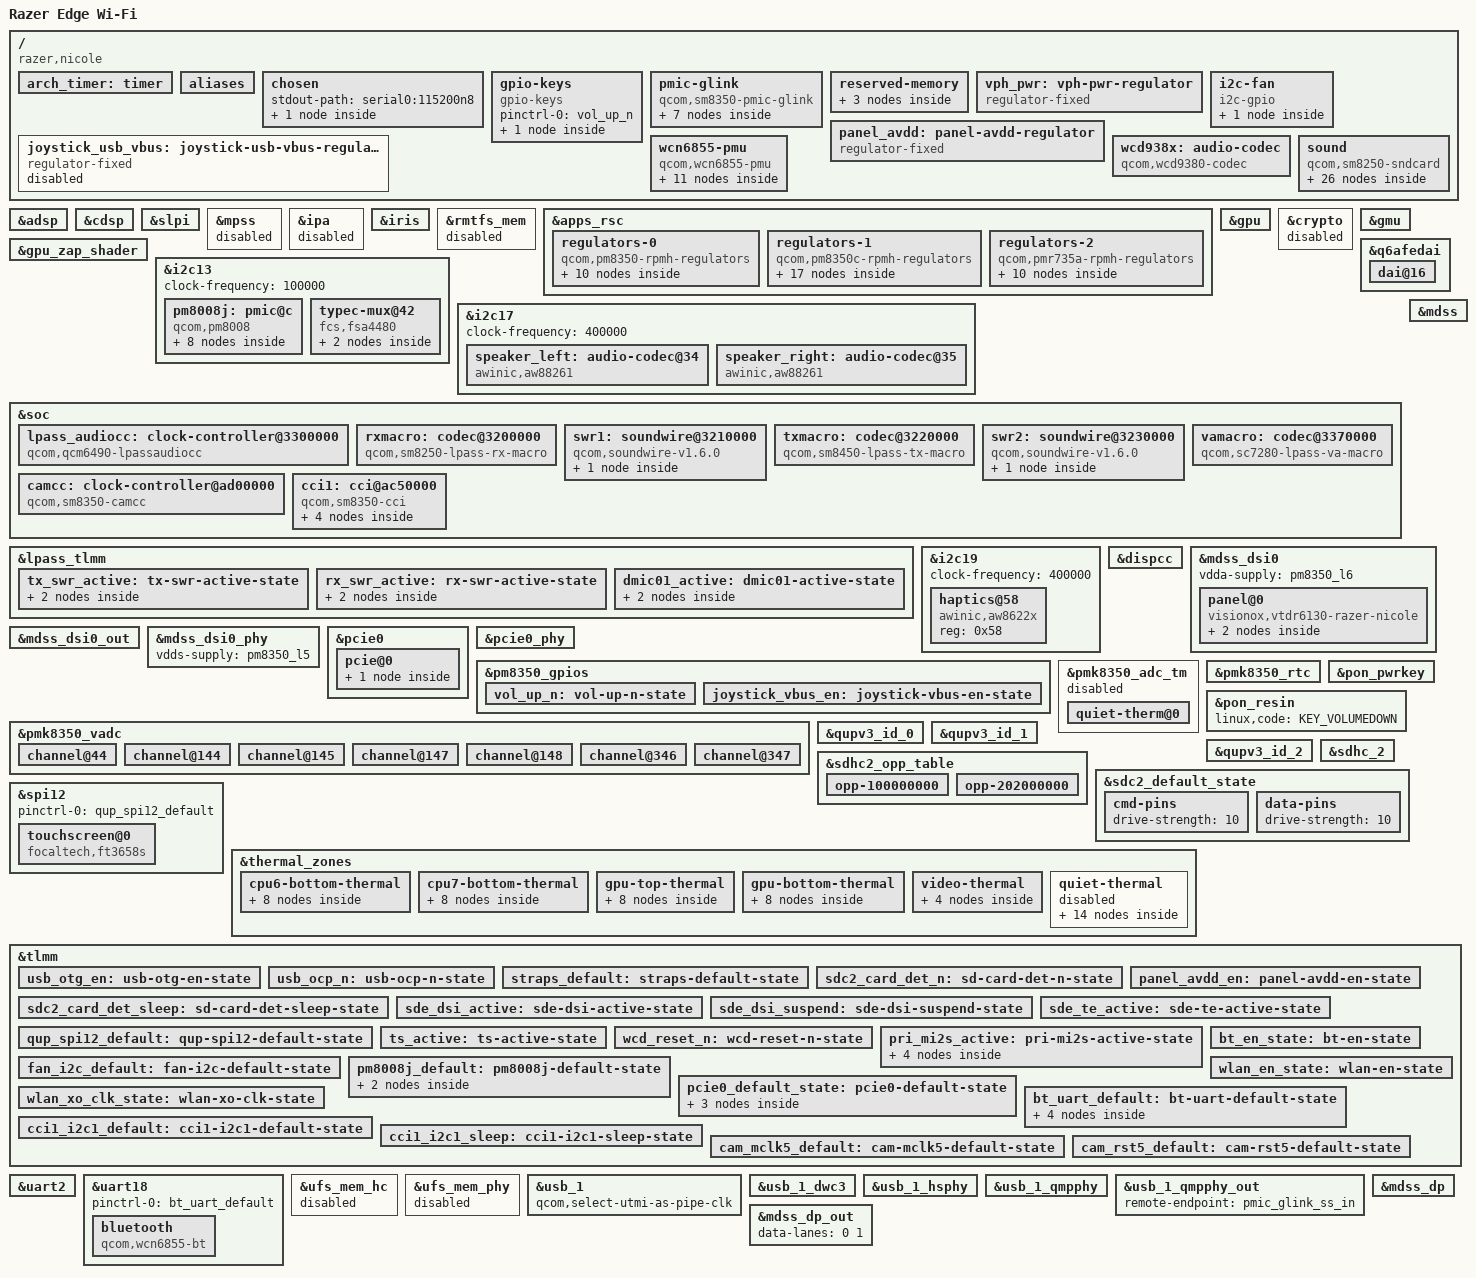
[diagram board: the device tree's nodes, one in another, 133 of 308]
// SPDX-License-Identifier: GPL-2.0-only
/*
 * Razer Edge Wi-Fi (RZ80-0461, codename "nicole")
 * Qualcomm SM8350 ("lahainap", marketed as Snapdragon G3x Gen 1), 6 GB RAM
 *
 * DRAFT mainline device tree - written before the device was connected.
 * Base structure follows sm8350-hdk.dts and sm8350-sony-xperia-sagami.dtsi.
 *
 * Source references (all paths relative to the Razer/LineageOS 5.4 kernel,
 * arch/arm64/boot/dts/vendor/qcom/ unless stated otherwise):
 *   nicole.dtsi   = lahainap-nicole.dtsi        (board file)
 *   qrd-common    = lahaina-qrd-common.dtsi     (included by nicole.dtsi:2)
 *   pmic-overlay  = lahaina-pmic-overlay.dtsi   (included by qrd-common:7)
 *   regulators    = lahaina-regulators.dtsi
 *   lahaina.dtsi  = SoC file (via lahainap.dtsi / lahainap-v2(.1).dtsi)
 *   pinctrl       = lahaina-pinctrl.dtsi
 * Effective downstream DT = lahainap*.dtb (base) + lahainap-nicole-overlay.dtbo
 * (Makefile:1-6, nicole.config CONFIG_BUILD_ARM64_DT_OVERLAY=y).
 *
 * PHASE RULES
 *   Phase 2 (first boot): microSD rootfs, USB gadget networking, simple-
 *   framebuffer console, buttons, remoteprocs. Internal UFS is DISABLED.
 *   Phase 3 nodes are present but status = "disabled" and marked PHASE 3.
 *
 * Anything marked TODO(cihaz) must be confirmed on the real device
 * (Phase 0 /sys/firmware/fdt dump, i2cdetect, gpioinfo, ...).
 */

/dts-v1/;

#include <dt-bindings/clock/qcom,lpassaudiocc-sc7280.h>
#include <dt-bindings/clock/qcom,sm8350-camcc.h>
#include <dt-bindings/gpio/gpio.h>
#include <dt-bindings/iio/qcom,spmi-adc7-pm8350.h>
#include <dt-bindings/iio/qcom,spmi-adc7-pm8350b.h>
#include <dt-bindings/iio/qcom,spmi-adc7-pmk8350.h>
#include <dt-bindings/input/input.h>
#include <dt-bindings/regulator/qcom,rpmh-regulator.h>
#include "sm8350.dtsi"
#include "pm8350.dtsi"
#include "pm8350b.dtsi"
#include "pm8350c.dtsi"
#include "pmk8350.dtsi"
#include "pmr735a.dtsi"
#include "pmr735b.dtsi"

/ {
	model = "Razer Edge Wi-Fi";
	compatible = "razer,nicole", "qcom,sm8350";
	chassis-type = "handset";

	/*
	 * ABL applies the Gunyah hypervisor's DTBOs on top of the DTB, and they
	 * reference the label "arch_timer" (Qualcomm's lahaina DT has it on the
	 * armv8 timer). Without it the overlay step fails and ABL drops to
	 * fastboot without a word (found 2026-10-25 by bisecting the __symbols__
	 * of LineageOS' SoC DTB, lab log). Build with -@.
	 */
	arch_timer: timer {
	};

	/*
	 * Downstream IDs: qcom,msm-id = <439 0x20001> (lahainap-v2.1.dtsi:6,
	 * 439 = QCOM_ID_SM8350 in mainline qcom,ids.h) and
	 * qcom,board-id = <0x1001f 0x02> (lahainap-nicole-overlay.dts:9).
	 * Sagami notes that adding msm/board-id on SM8350 can upset ABL, so they
	 * are left out on purpose. TODO(cihaz): if ABL refuses the DTB in
	 * "fastboot boot", try uncommenting these two lines:
	 *
	 * qcom,msm-id = <439 0x20001>;
	 * qcom,board-id = <0x1001f 0x02>;
	 */

	aliases {
		/* QUP SE3 debug UART @98c000, GPIO18/19 (lahaina-qupv3.dtsi:72-85,
		 * lahaina.dtsi:46 serial0). TODO(cihaz): test pads unknown. */
		serial0 = &uart2;
		mmc1 = &sdhc_2;
	};

	chosen {
		#address-cells = <2>;
		#size-cells = <2>;
		ranges;

		/*
		 * Kernel messages go to the debug UART (if pads are reachable);
		 * add "console=tty0" to the cmdline so the framebuffer console
		 * gets them too (see docs/dts-notlari.md).
		 */
		stdout-path = "serial0:115200n8";

		/*
		 * Bootloader continuous-splash framebuffer.
		 * Region: splash_memory "cont_splash_region" reg <0xe1000000 0x2300000>
		 * (lahaina.dtsi:516-519); disp_rdump_region uses the same base
		 * (display/lahaina-sde.dtsi:5-8). Panel is 1080x2400
		 * (display/dsi-panel-vtdr6130-dsc-fhd-plus-144hz-cmd.dtsi:54-55).
		 * 1080*2400*4 = 0x9e3400 bytes fits in the region.
		 * TODO(cihaz): verify format (a8r8g8b8 vs x8r8g8b8/r8g8b8) and
		 * stride (no padding assumed) by checking the picture on screen.
		 * The panel is mounted rotated (downstream qcom,mdss-dsi-panel-
		 * orientation = "180", panel dtsi:40; Android boots landscape,
		 * vendor.prop:101 ORIENTATION_90) -> use fbcon=rotate:N.
		 */
		framebuffer0: framebuffer@e1000000 {
			compatible = "simple-framebuffer";
			reg = <0x0 0xe1000000 0x0 0x2300000>;
			width = <1080>;
			height = <2400>;
			stride = <(1080 * 4)>;
			format = "a8r8g8b8";

			/*
			 * Keep the display path alive until a real DRM driver
			 * takes over: AXI clocks, MDSS GDSC (keeps MMCX up through
			 * the genpd hierarchy) and every rail the panel + DSI need,
			 * otherwise regulator/genpd/rpmhpd cleanup ~30 s after boot
			 * blanks the screen.
			 */
			clocks = <&gcc GCC_DISP_HF_AXI_CLK>,
				 <&gcc GCC_DISP_SF_AXI_CLK>;
			/*
			 * MMCX directly, not <&dispcc MDSS_GDSC>: dispcc stays disabled
			 * (see &dispcc below), the bootloader leaves MDSS_GDSC on.
			 * The HF TBUs carry the MDSS scanout through the SMMU; without
			 * pd_ignore_unused nothing else keeps them on.
			 */
			power-domains = <&rpmhpd RPMHPD_MMCX>,
					<&gcc HLOS1_VOTE_MMNOC_MMU_TBU_HF0_GDSC>,
					<&gcc HLOS1_VOTE_MMNOC_MMU_TBU_HF1_GDSC>;
			/*
			 * MDP scanout paths (sm8350.dtsi &mdss "mdp0-mem"/"mdp1-mem").
			 * Without a vote here the NoC stalls once the interconnect
			 * providers reach sync_state() (lab log, 25 Ekim);
			 * needs drivers/simpledrm/0001-...interconnect-bandwidth.patch.
			 */
			interconnects = <&mmss_noc MASTER_MDP0 0 &mc_virt SLAVE_EBI1 0>,
					<&mmss_noc MASTER_MDP1 0 &mc_virt SLAVE_EBI1 0>;
			vddio-supply = <&pm8350c_l12>;	/* panel vddio, display/lahaina-sde-display.dtsi:98 */
			vci-supply = <&pm8350c_l13>;	/* panel vdd 3.0 V, display/lahaina-sde-display.dtsi:99 */
			avdd-supply = <&panel_avdd>;	/* GPIO13 switch, nicole.dtsi:295-299 */
			dsi-vdda-supply = <&pm8350_l6>;	/* DSI 1.2 V, display/lahaina-sde.dtsi:90 */
			dsi-phy-supply = <&pm8350_l5>;	/* DSI PHY: lahaina-sde.dtsi:267 overrides :91 to L5B (0.88 V; downstream supply entry asks 0.912 V - TODO(cihaz): check regulators.txt) */
		};
	};

	gpio-keys {
		compatible = "gpio-keys";

		pinctrl-0 = <&vol_up_n>;
		pinctrl-names = "default";

		/* qrd-common:306-323 vol_up = pm8350_gpios 6, active low */
		key-vol-up {
			label = "Volume Up";
			linux,code = <KEY_VOLUMEUP>;
			gpios = <&pm8350_gpios 6 GPIO_ACTIVE_LOW>;
			debounce-interval = <15>;
			linux,can-disable;
			wakeup-source;
		};
	};

	/*
	 * Battery / charger through the ADSP (battery_charger, ucsi, altmode under
	 * qcom,pmic_glink, lahaina.dtsi:5558-5581). Enabled 2026-10-25 with the
	 * device's own adsp.mbn (Faz 3 extraction): qcom-battmgr reports status,
	 * capacity, voltage, current, temp; the ADSP charges by itself.
	 * Needs "qcom,sm8350" in the LIVE root compatible for the in-kernel PD mapper
	 * (the dtbo overlay used to replace it, see make-bootimg.sh d5 dtbo).
	 *
	 * D2 deneme C (31 Ekim): the Type-C graph as sm8350-hdk.dts:41-82: SS to
	 * usb_1_qmpphy (no redriver: NB7VPQ904M is QRD-only), SBU to the FSA4480,
	 * orientation from GPIO81 usb3phy_portselect (pinctrl:3652-3678), mdss_dp
	 * on two lanes. Razer's own DP node uses the same FSA4480 as AUX switch and
	 * the ADSP altmode for HPD (display/lahaina-sde.dtsi sde_dp).
	 */
	pmic-glink {
		compatible = "qcom,sm8350-pmic-glink", "qcom,pmic-glink";
		#address-cells = <1>;
		#size-cells = <0>;
		/* GPIO81 usb3phy_portselect (pinctrl:3652-3678), as sm8350-hdk */
		orientation-gpios = <&tlmm 81 GPIO_ACTIVE_HIGH>;

		/*
		 * Razer's OTG load switch (31 Ekim 2026): their 5.4 kernel drives
		 * global GPIO 356 high on battmgr notification 0x91 / a UFP partner
		 * and low on 0x90 (qti_battery_charger.c, ucsi.c). That is TLMM 48
		 * (TLMM base 308), the "ocp,control-gpio" of their qcom_ocp node;
		 * GPIO79 is the switch's active-low over-current flag, pulled up
		 * (nicole.dtsi:347-358, 501-508, drivers/soc/qcom/ocp_irq.c).
		 * Verified: a hub enumerates the moment 48 goes high and drops when
		 * it goes low. Keep GPIO78 ("usb_charge_contrl") low: with it high
		 * the hub never powered up. Consumer: drivers/typec ucsi_glink patch.
		 */
		otg-gpios = <&tlmm 48 GPIO_ACTIVE_HIGH>;
		ocp-gpios = <&tlmm 79 GPIO_ACTIVE_LOW>;
		pinctrl-0 = <&usb_otg_en>, <&usb_ocp_n>;
		pinctrl-names = "default";

		/*
		 * With the Type-C graph (altmode on) the ADSP's charger detection
		 * leaves the HS PHY non-driving, datapath overridden (CFG0 bit0,
		 * UTMI_CTRL0 OPMODE=01), ~11 ms after every sink attach: the Mac
		 * sees a dead device. ucsi_glink hands the datapath back through
		 * this PHY (31 Ekim 2026, measured with a 10 ms register watch).
		 */
		phys = <&usb_1_hsphy>;
		phy-names = "usb2";

		connector@0 {
			compatible = "usb-c-connector";
			reg = <0>;
			power-role = "dual";
			data-role = "dual";

			ports {
				#address-cells = <1>;
				#size-cells = <0>;

				/*
				 * No HS endpoint: wired to dwc3 it hands UCSI the role
				 * switch and device mode stalls (D1 deneme 1, D2 deneme
				 * C/E, 31 Ekim). nicole-usb-rol copies the role instead.
				 */
				port@0 {
					reg = <0>;
				};

				port@1 {
					reg = <1>;

					pmic_glink_ss_in: endpoint {
						remote-endpoint = <&usb_1_qmpphy_out>;
					};
				};

				port@2 {
					reg = <2>;

					pmic_glink_sbu: endpoint {
						remote-endpoint = <&fsa4480_sbu_mux>;
					};
				};
			};
		};
	};

	reserved-memory {
		/*
		 * All fixed carveouts of Razer's lahaina.dtsi:293-417 match
		 * mainline sm8350.dtsi:425-555 byte for byte (hyp, xbl_aop,
		 * cmd_db, smem, cpucp, cdsp_secure_heap, camera, video, cvp,
		 * adsp 0x86100000+0x2100000, slpi 0x88200000+0x1500000,
		 * cdsp 0x89700000+0x1e00000, ipa fw/gsi, gpu 0x8b51a000+0x2000,
		 * spss, modem 0x8b800000+0x10000000, hyp_reserved, trustedvm,
		 * qrtr/neuron shbufs, removed_mem). Only display regions are added
		 * here; rmtfs is handled below (&rmtfs_mem).
		 */

		/* lahaina.dtsi:516-519 (downstream has no no-map; we must not
		 * let Linux allocate the live scanout buffer) */
		cont_splash_mem: memory@e1000000 {
			reg = <0x0 0xe1000000 0x0 0x2300000>;
			no-map;
		};

		/* lahaina.dtsi:535-538 dfps_data_region, written by ABL */
		dfps_data_mem: memory@e3300000 {
			reg = <0x0 0xe3300000 0x0 0x100000>;
			no-map;
		};

		/*
		 * Crash log across a warm reset (pstore). Razer's DT has no such
		 * region; 0xffc00000 is what the other sm8350 phone in mainline
		 * uses (sm8350-sony-xperia-sagami.dtsi). On nicole it is plain
		 * System RAM (in Linux's CMA area, which simply moves). Added for
		 * the first suspend test (30 Ekim): the phone reset with no log.
		 */
		ramoops@ffc00000 {
			compatible = "ramoops";
			reg = <0x0 0xffc00000 0x0 0x100000>;
			record-size = <0x10000>;
			console-size = <0x40000>;
			pmsg-size = <0x20000>;
			ecc-size = <16>;
			no-map;
		};
	};

	vph_pwr: vph-pwr-regulator {
		compatible = "regulator-fixed";
		regulator-name = "vph_pwr";
		regulator-min-microvolt = <3700000>;
		regulator-max-microvolt = <3700000>;

		regulator-always-on;
		regulator-boot-on;
	};

	/*
	 * Panel AVDD load switch. Downstream: "display_panel_avdd" 5.5 V
	 * (display/lahaina-sde-display.dtsi:21-34) re-pointed by nicole to
	 * GPIO13, active LOW (nicole.dtsi:295-299, 320-330).
	 * regulator-boot-on: keep it on, the splash screen is using it.
	 */
	panel_avdd: panel-avdd-regulator {
		compatible = "regulator-fixed";
		regulator-name = "panel_avdd";
		regulator-min-microvolt = <5500000>;
		regulator-max-microvolt = <5500000>;
		regulator-enable-ramp-delay = <233>;
		gpio = <&tlmm 13 GPIO_ACTIVE_LOW>;
		regulator-boot-on;

		pinctrl-0 = <&panel_avdd_en>;
		pinctrl-names = "default";
	};

	/*
	 * PHASE 3: 5 V boost for the detachable controller ("joystick"),
	 * pm8350_gpios 8, always-on downstream (nicole.dtsi:542-553).
	 * TODO(cihaz): find out how the controller is wired (USB? usb1 is
	 * disabled on nicole, nicole.dtsi:577-587).
	 */
	joystick_usb_vbus: joystick-usb-vbus-regulator {
		compatible = "regulator-fixed";
		regulator-name = "joystick_usb_vbus";
		regulator-min-microvolt = <5000000>;
		regulator-max-microvolt = <5000000>;
		regulator-enable-ramp-delay = <600>;
		gpio = <&pm8350_gpios 8 GPIO_ACTIVE_HIGH>;
		enable-active-high;

		pinctrl-0 = <&joystick_vbus_en>;
		pinctrl-names = "default";

		status = "disabled";
	};

	/*
	 * PHASE 3: bit-banged I2C bus for the fan controller.
	 * nicole.dtsi:512-524: SDA GPIO8, SCL GPIO9, open drain, 5 us delay,
	 * pins pull-up / 16 mA (nicole.dtsi:449-460).
	 */
	i2c-fan {
		compatible = "i2c-gpio";
		sda-gpios = <&tlmm 8 (GPIO_ACTIVE_HIGH | GPIO_OPEN_DRAIN)>;
		scl-gpios = <&tlmm 9 (GPIO_ACTIVE_HIGH | GPIO_OPEN_DRAIN)>;
		i2c-gpio,delay-us = <5>;
		#address-cells = <1>;
		#size-cells = <0>;

		pinctrl-0 = <&fan_i2c_default>;
		pinctrl-names = "default";

		status = "okay";

		/*
		 * MAX31760 @0x50 (nicole.dtsi:526-539). Mainline driver
		 * drivers/hwmon/max31760.c ("adi,max31760") has NO regulator,
		 * GPIO or cooling-device support and the binding
		 * (hwmon/adi,max31760.yaml) has additionalProperties: false.
		 * The supply / GPIO / #cooling-cells properties below are a
		 * PROPOSED binding extension (driver work needed):
		 *   vdd  = pm8008j_l7, driver forces 3.3 V (max31760_fan.c:28-29)
		 *   fan  = pm8008j_l6, 2.8-2.9 V "VDD_FAN" (max31760_fan.c:30-31)
		 *   vcca = pm8350_s10, 1.8 V (max31760_fan.c:37-38)
		 *   GPIO78 "usb_charge_contrl", driven 0 at probe (max31760_fan.c:370-383)
		 *   GPIO93 "dpr_contrl", driven 1 at probe (max31760_fan.c:385-397)
		 * Fan levels 0..7 -> duty {0x00,0x4e,0x71,0x97,0xb2,0xcc,0xe8,0xff}
		 * (max31760_fan.c:80). docs/guvenlik-kurallari.md forbids turning the fan off.
		 */
		fancontroller: fan-controller@50 {
			compatible = "adi,max31760";
			reg = <0x50>;
			#cooling-cells = <2>;

			vdd-supply = <&pm8008j_l7>;
			fan-supply = <&pm8008j_l6>;
			vcca-supply = <&pm8350_s10>;
			usb-charge-en-gpios = <&tlmm 78 GPIO_ACTIVE_HIGH>;
			dpr-en-gpios = <&tlmm 93 GPIO_ACTIVE_HIGH>;
		};
	};

	/*
	 * PHASE 3: QCA6490 Wi-Fi/BT power sequencer (WCN6855 family,
	 * modelled on sm8450-hdk.dts). GPIOs: WLAN_EN 64, BT_EN 65,
	 * SW_CTRL 153 (lahaina.dtsi:5380-5382, 5646-5648), XO clock GPIO201
	 * (nicole.dtsi:5-12). Supplies from lahaina.dtsi:5395-5406 and
	 * 5649-5659: aon S2E, dig S11B, io S10B, rfa1 S1C, rfa2 S12B,
	 * antenna switch L7E. TODO(cihaz): the exact pmu-input mapping is
	 * inferred (downstream names differ from the mainline PMU inputs).
	 */
	wcn6855-pmu {
		compatible = "qcom,wcn6855-pmu";

		pinctrl-0 = <&bt_en_state>, <&wlan_en_state>, <&wlan_xo_clk_state>;
		pinctrl-names = "default";

		wlan-enable-gpios = <&tlmm 64 GPIO_ACTIVE_HIGH>;
		bt-enable-gpios = <&tlmm 65 GPIO_ACTIVE_HIGH>;
		swctrl-gpios = <&tlmm 153 GPIO_ACTIVE_HIGH>;
		xo-clk-gpios = <&tlmm 201 GPIO_ACTIVE_HIGH>;

		vddio-supply = <&pm8350_s10>;
		vddaon-supply = <&pmr735a_s2>;
		vddpmu-supply = <&pm8350_s12>;
		vddpmumx-supply = <&pmr735a_s2>;
		vddpmucx-supply = <&pm8350_s11>;
		vddrfa0p95-supply = <&pm8350_s11>;
		vddrfa1p3-supply = <&pm8350_s12>;
		vddrfa1p9-supply = <&pm8350c_s1>;
		vddpcie1p3-supply = <&pm8350_s12>;
		vddpcie1p9-supply = <&pm8350c_s1>;


		regulators {
			vreg_pmu_rfa_cmn_0p8: ldo0 {
				regulator-name = "vreg_pmu_rfa_cmn_0p8";
			};

			vreg_pmu_aon_0p8: ldo1 {
				regulator-name = "vreg_pmu_aon_0p8";
			};

			vreg_pmu_wlcx_0p8: ldo2 {
				regulator-name = "vreg_pmu_wlcx_0p8";
			};

			vreg_pmu_wlmx_0p8: ldo3 {
				regulator-name = "vreg_pmu_wlmx_0p8";
			};

			vreg_pmu_btcmx_0p8: ldo4 {
				regulator-name = "vreg_pmu_btcmx_0p8";
			};

			vreg_pmu_pcie_1p8: ldo5 {
				regulator-name = "vreg_pmu_pcie_1p8";
			};

			vreg_pmu_pcie_0p9: ldo6 {
				regulator-name = "vreg_pmu_pcie_0p9";
			};

			vreg_pmu_rfa_0p8: ldo7 {
				regulator-name = "vreg_pmu_rfa_0p8";
			};

			vreg_pmu_rfa_1p2: ldo8 {
				regulator-name = "vreg_pmu_rfa_1p2";
			};

			vreg_pmu_rfa_1p7: ldo9 {
				regulator-name = "vreg_pmu_rfa_1p7";
			};
		};
	};
};

/*
 * Remoteprocs. Carveouts identical to mainline (see reserved-memory).
 * Downstream PAS ids: adsp 1 (lahaina.dtsi:4492), cdsp 18 (:4539),
 * slpi 12 (:5125) - same as mainline sm8350-adsp/cdsp/slpi-pas.
 * Firmware comes from the device's modem/NON-HLOS partition as split
 * .mdt/.bNN files; squash to .mbn (pil-squasher) into
 * /lib/firmware/qcom/sm8350/razer/nicole/. If the files are absent the
 * remoteproc simply stays offline.
 */
&adsp {
	firmware-name = "qcom/sm8350/razer/nicole/adsp.mbn";
	status = "okay";
};

&cdsp {
	firmware-name = "qcom/sm8350/razer/nicole/cdsp.mbn";
	status = "okay";
};

&slpi {
	firmware-name = "qcom/sm8350/razer/nicole/slpi.mbn";
	status = "okay";
};

/*
 * Wi-Fi SKU: no modem. The 5G SKU uses an external Quectel module
 * (nicole.dtsi:494-499, lineage-device init.target.rc Quectel RIL), so
 * MPSS stays disabled (sm8350.dtsi default) and IPA too (lahainap.dtsi:9-11
 * disables ipa_hw).
 */
&mpss {
	status = "disabled";
};

&ipa {
	status = "disabled";
};

/*
 * D4 (31 Ekim 2026): hardware video decode/encode (iris, VPU 2.0). The firmware is the
 * device's own, signed for this SoC: vendor/firmware/vpu20_4v.mbn (lahaina-vidc.dtsi:37),
 * put on the phone by scripts/lab/video-firmware.sh, never packaged. linux-firmware has
 * no sm8350 VPU file (sm8350-hdk's vpu20_p4_sm8350.mbn is not in it). pil_video_mem
 * (0x85700000+0x500000, sm8350.dtsi) is Razer's carveout too (lahaina.dtsi:339-342).
 */
&iris {
	firmware-name = "qcom/sm8350/razer/nicole/vpu20_4v.mbn";

	status = "okay";
};

/*
 * Mainline reserves rmtfs at a fixed 0x9b800000+0x280000; Razer allocates
 * rmtfs dynamically (qcom,rmtfs_sharedmem reg <0 0x280000>,
 * lahaina.dtsi:3026-3031), so Android uses that range as normal RAM.
 * Only the modem needs rmtfs -> drop the carveout.
 */
&rmtfs_mem {
	status = "disabled";
};

&apps_rsc {
	/*
	 * PM8350 (PMIC "b"). Voltages = lahaina-regulators.dtsi ranges
	 * (never wider). Labels follow the downstream names so that
	 * S10B == pm8350_s10, L5B == pm8350_l5 etc.
	 * ARC (level) rails S5/S6/S9/L4/L8 are not listed.
	 */
	regulators-0 {
		compatible = "qcom,pm8350-rpmh-regulators";
		qcom,pmic-id = "b";

		vdd-s1-supply = <&vph_pwr>;
		vdd-s2-supply = <&vph_pwr>;
		vdd-s3-supply = <&vph_pwr>;
		vdd-s4-supply = <&vph_pwr>;
		vdd-s5-supply = <&vph_pwr>;
		vdd-s6-supply = <&vph_pwr>;
		vdd-s7-supply = <&vph_pwr>;
		vdd-s8-supply = <&vph_pwr>;
		vdd-s9-supply = <&vph_pwr>;
		vdd-s10-supply = <&vph_pwr>;
		vdd-s11-supply = <&vph_pwr>;
		vdd-s12-supply = <&vph_pwr>;

		vdd-l1-l4-supply = <&pm8350_s11>;
		vdd-l2-l7-supply = <&vreg_bob>;
		vdd-l3-l5-supply = <&vreg_bob>;
		vdd-l6-l9-l10-supply = <&pm8350_s11>;

		/* regulators:121-126 */
		pm8350_s10: smps10 {
			regulator-name = "pm8350_s10";
			regulator-min-microvolt = <1800000>;
			regulator-max-microvolt = <1800000>;
			regulator-initial-mode = <RPMH_REGULATOR_MODE_HPM>;
		};

		/* regulators:133-138 */
		pm8350_s11: smps11 {
			regulator-name = "pm8350_s11";
			regulator-min-microvolt = <752000>;
			regulator-max-microvolt = <1012000>;
			regulator-initial-mode = <RPMH_REGULATOR_MODE_HPM>;
		};

		/* regulators:150-156 */
		pm8350_s12: smps12 {
			regulator-name = "pm8350_s12";
			regulator-min-microvolt = <1224000>;
			regulator-max-microvolt = <1360000>;
			regulator-initial-mode = <RPMH_REGULATOR_MODE_HPM>;
		};

		/* regulators:168-174, DSI PHY 0.9 V + USB QMP PHY */
		pm8350_l1: ldo1 {
			regulator-name = "pm8350_l1";
			regulator-min-microvolt = <912000>;
			regulator-max-microvolt = <920000>;
			regulator-initial-mode = <RPMH_REGULATOR_MODE_HPM>;
		};

		/* regulators:187-193, USB HS PHY 3.1 V */
		pm8350_l2: ldo2 {
			regulator-name = "pm8350_l2";
			regulator-min-microvolt = <3072000>;
			regulator-max-microvolt = <3072000>;
			regulator-initial-mode = <RPMH_REGULATOR_MODE_HPM>;
		};

		/* regulators:207-213 */
		pm8350_l3: ldo3 {
			regulator-name = "pm8350_l3";
			regulator-min-microvolt = <904000>;
			regulator-max-microvolt = <904000>;
			regulator-initial-mode = <RPMH_REGULATOR_MODE_HPM>;
		};

		/* regulators:242-248, USB HS PHY / UFS PHY / PCIe 0.88 V */
		pm8350_l5: ldo5 {
			regulator-name = "pm8350_l5";
			regulator-min-microvolt = <880000>;
			regulator-max-microvolt = <888000>;
			regulator-initial-mode = <RPMH_REGULATOR_MODE_HPM>;
			/*
			 * Fixed HPM (no allow-set-load / LPM), a precaution: shared PHY rail
			 * (USB HS PHY PLL, UFS PHY, DSI PHY) and the USB PHY votes no load,
			 * so a UFS PHY load drop could otherwise put it in LPM. (The NCM
			 * link failures of 2026-10-25 that prompted this were the Mac's
			 * screen lock holding back new USB accessories, not this rail.)
			 */
			regulator-allowed-modes = <RPMH_REGULATOR_MODE_HPM>;
		};

		/* regulators:282-288, DSI 1.2 V / PHY PLLs */
		pm8350_l6: ldo6 {
			regulator-name = "pm8350_l6";
			regulator-min-microvolt = <1200000>;
			regulator-max-microvolt = <1208000>;
			regulator-initial-mode = <RPMH_REGULATOR_MODE_HPM>;
			/*
			 * Fixed HPM (no allow-set-load / LPM), a precaution: shared PHY rail
			 * (USB HS PHY PLL, UFS PHY, DSI PHY) and the USB PHY votes no load,
			 * so a UFS PHY load drop could otherwise put it in LPM. (The NCM
			 * link failures of 2026-10-25 that prompted this were the Mac's
			 * screen lock holding back new USB accessories, not this rail.)
			 */
			regulator-allowed-modes = <RPMH_REGULATOR_MODE_HPM>;
		};

		/* regulators:302-308, UFS VCC (UFS disabled in phase 2) */
		pm8350_l7: ldo7 {
			regulator-name = "pm8350_l7";
			regulator-min-microvolt = <2400000>;
			regulator-max-microvolt = <3008000>;
			regulator-initial-mode = <RPMH_REGULATOR_MODE_HPM>;
			regulator-allow-set-load;
			regulator-allowed-modes = <RPMH_REGULATOR_MODE_LPM
						   RPMH_REGULATOR_MODE_HPM>;
		};

		/* regulators:336-342, UFS VCCQ */
		pm8350_l9: ldo9 {
			regulator-name = "pm8350_l9";
			regulator-min-microvolt = <1200000>;
			regulator-max-microvolt = <1200000>;
			regulator-initial-mode = <RPMH_REGULATOR_MODE_HPM>;
			regulator-allow-set-load;
			regulator-allowed-modes = <RPMH_REGULATOR_MODE_LPM
						   RPMH_REGULATOR_MODE_HPM>;
		};
	};

	/* PM8350C (PMIC "c"). ARC rails S2/S4/S6/S8 not listed. */
	regulators-1 {
		compatible = "qcom,pm8350c-rpmh-regulators";
		qcom,pmic-id = "c";

		vdd-s1-supply = <&vph_pwr>;
		vdd-s2-supply = <&vph_pwr>;
		vdd-s3-supply = <&vph_pwr>;
		vdd-s4-supply = <&vph_pwr>;
		vdd-s5-supply = <&vph_pwr>;
		vdd-s6-supply = <&vph_pwr>;
		vdd-s7-supply = <&vph_pwr>;
		vdd-s8-supply = <&vph_pwr>;
		vdd-s9-supply = <&vph_pwr>;
		vdd-s10-supply = <&vph_pwr>;

		vdd-l1-l12-supply = <&pm8350c_s1>;
		vdd-l2-l8-supply = <&pm8350c_s1>;
		vdd-l3-l4-l5-l7-l13-supply = <&vreg_bob>;
		vdd-l6-l9-l11-supply = <&vreg_bob>;
		vdd-l10-supply = <&pm8350_s12>;

		vdd-bob-supply = <&vph_pwr>;

		/* regulators:349-354 */
		pm8350c_s1: smps1 {
			regulator-name = "pm8350c_s1";
			regulator-min-microvolt = <1800000>;
			regulator-max-microvolt = <1952000>;
			regulator-initial-mode = <RPMH_REGULATOR_MODE_HPM>;
		};

		/* regulators:377-382 */
		pm8350c_s3: smps3 {
			regulator-name = "pm8350c_s3";
			regulator-min-microvolt = <300000>;
			regulator-max-microvolt = <704000>;
			regulator-initial-mode = <RPMH_REGULATOR_MODE_HPM>;
		};

		/* regulators:504-509 */
		pm8350c_s10: smps10 {
			regulator-name = "pm8350c_s10";
			regulator-min-microvolt = <1048000>;
			regulator-max-microvolt = <1128000>;
			regulator-initial-mode = <RPMH_REGULATOR_MODE_HPM>;
		};

		/* regulators:522-528, USB HS PHY 1.8 V */
		pm8350c_l1: ldo1 {
			regulator-name = "pm8350c_l1";
			regulator-min-microvolt = <1800000>;
			regulator-max-microvolt = <1800000>;
			regulator-initial-mode = <RPMH_REGULATOR_MODE_HPM>;
		};

		/* regulators:561-567 */
		pm8350c_l2: ldo2 {
			regulator-name = "pm8350c_l2";
			regulator-min-microvolt = <1800000>;
			regulator-max-microvolt = <1800000>;
			regulator-initial-mode = <RPMH_REGULATOR_MODE_HPM>;
		};

		/* regulators:579-585 - touch vdd (nicole.dtsi:156). NOTE: Razer
		 * fixes L3C at 3.008 V (sagami uses 3.304 V - do not copy). */
		pm8350c_l3: ldo3 {
			regulator-name = "pm8350c_l3";
			regulator-min-microvolt = <3008000>;
			regulator-max-microvolt = <3008000>;
			regulator-initial-mode = <RPMH_REGULATOR_MODE_HPM>;
		};

		/* regulators:597-603 */
		pm8350c_l4: ldo4 {
			regulator-name = "pm8350c_l4";
			regulator-min-microvolt = <1704000>;
			regulator-max-microvolt = <3000000>;
			regulator-initial-mode = <RPMH_REGULATOR_MODE_HPM>;
		};

		/* regulators:615-621 */
		pm8350c_l5: ldo5 {
			regulator-name = "pm8350c_l5";
			regulator-min-microvolt = <1704000>;
			regulator-max-microvolt = <3000000>;
			regulator-initial-mode = <RPMH_REGULATOR_MODE_HPM>;
		};

		/* regulators:634-640 - SD card I/O (qrd-common:45-46 asks
		 * 1.808-2.96 V) */
		pm8350c_l6: ldo6 {
			regulator-name = "pm8350c_l6";
			regulator-min-microvolt = <1800000>;
			regulator-max-microvolt = <2960000>;
			regulator-initial-mode = <RPMH_REGULATOR_MODE_HPM>;
		};

		/* regulators:654-660 */
		pm8350c_l7: ldo7 {
			regulator-name = "pm8350c_l7";
			regulator-min-microvolt = <3008000>;
			regulator-max-microvolt = <3008000>;
			regulator-initial-mode = <RPMH_REGULATOR_MODE_HPM>;
		};

		/* regulators:672-678 - touch vcc_i2c / iovdd (nicole.dtsi:157) */
		pm8350c_l8: ldo8 {
			regulator-name = "pm8350c_l8";
			regulator-min-microvolt = <1800000>;
			regulator-max-microvolt = <1800000>;
			regulator-initial-mode = <RPMH_REGULATOR_MODE_HPM>;
		};

		/*
		 * regulators:691-697 allows 2.96-3.008 V; the SD consumer asks
		 * 2.95-2.96 V (qrd-common:41-42). Clamp max to 2.96 V like
		 * sagami (SDHCI expects 2.96 V) - still inside Razer's range.
		 */
		pm8350c_l9: ldo9 {
			regulator-name = "pm8350c_l9";
			regulator-min-microvolt = <2960000>;
			regulator-max-microvolt = <2960000>;
			regulator-initial-mode = <RPMH_REGULATOR_MODE_HPM>;
		};

		/* regulators:711-717 */
		pm8350c_l10: ldo10 {
			regulator-name = "pm8350c_l10";
			regulator-min-microvolt = <1200000>;
			regulator-max-microvolt = <1200000>;
			regulator-initial-mode = <RPMH_REGULATOR_MODE_HPM>;
		};

		/* regulators:729-735 */
		pm8350c_l11: ldo11 {
			regulator-name = "pm8350c_l11";
			regulator-min-microvolt = <2400000>;
			regulator-max-microvolt = <3008000>;
			regulator-initial-mode = <RPMH_REGULATOR_MODE_HPM>;
		};

		/* regulators:748-754 - panel vddio, nicole sets 1.86 V
		 * (nicole.dtsi:302-305) */
		pm8350c_l12: ldo12 {
			regulator-name = "pm8350c_l12";
			regulator-min-microvolt = <1800000>;
			regulator-max-microvolt = <2000000>;
			regulator-initial-mode = <RPMH_REGULATOR_MODE_HPM>;
		};

		/* regulators:769-775 - panel vdd/vci 3.0 V
		 * (display/lahaina-sde-display-common.dtsi:49-57) */
		pm8350c_l13: ldo13 {
			regulator-name = "pm8350c_l13";
			regulator-min-microvolt = <3000000>;
			regulator-max-microvolt = <3000000>;
			regulator-initial-mode = <RPMH_REGULATOR_MODE_HPM>;
		};

		/* regulators:784-789 */
		vreg_bob: bob {
			regulator-name = "pm8350c_bob";
			regulator-min-microvolt = <3008000>;
			regulator-max-microvolt = <3960000>;
			regulator-initial-mode = <RPMH_REGULATOR_MODE_AUTO>;
		};
	};

	/*
	 * PM8350B L1 ("ldod1", 1.2 V, regulators:801-807) is not described:
	 * same situation as sagami (no mainline rpmh entry used so far).
	 */

	/* PMR735A (PMIC "e"), regulators:814-969 */
	regulators-2 {
		compatible = "qcom,pmr735a-rpmh-regulators";
		qcom,pmic-id = "e";

		vdd-s1-supply = <&vph_pwr>;
		vdd-s2-supply = <&vph_pwr>;
		vdd-s3-supply = <&vph_pwr>;

		vdd-l1-l2-supply = <&pmr735a_s2>;
		vdd-l3-supply = <&pmr735a_s1>;
		vdd-l4-supply = <&pm8350c_s1>;
		vdd-l5-l6-supply = <&pm8350c_s1>;
		vdd-l7-bob-supply = <&vreg_bob>;

		pmr735a_s1: smps1 {
			regulator-name = "pmr735a_s1";
			regulator-min-microvolt = <1200000>;
			regulator-max-microvolt = <1280000>;
		};

		/* Wi-Fi "aon" rail (lahaina.dtsi:5395-5396 asks 1.012 V) */
		pmr735a_s2: smps2 {
			regulator-name = "pmr735a_s2";
			regulator-min-microvolt = <500000>;
			regulator-max-microvolt = <1020000>;
		};

		pmr735a_s3: smps3 {
			regulator-name = "pmr735a_s3";
			regulator-min-microvolt = <2200000>;
			regulator-max-microvolt = <2352000>;
		};

		pmr735a_l1: ldo1 {
			regulator-name = "pmr735a_l1";
			regulator-min-microvolt = <912000>;
			regulator-max-microvolt = <912000>;
		};

		pmr735a_l2: ldo2 {
			regulator-name = "pmr735a_l2";
			regulator-min-microvolt = <1200000>;
			regulator-max-microvolt = <1200000>;
		};

		pmr735a_l3: ldo3 {
			regulator-name = "pmr735a_l3";
			regulator-min-microvolt = <1200000>;
			regulator-max-microvolt = <1200000>;
		};

		pmr735a_l4: ldo4 {
			regulator-name = "pmr735a_l4";
			regulator-min-microvolt = <1776000>;
			regulator-max-microvolt = <1872000>;
		};

		pmr735a_l5: ldo5 {
			regulator-name = "pmr735a_l5";
			regulator-min-microvolt = <800000>;
			regulator-max-microvolt = <800000>;
		};

		pmr735a_l6: ldo6 {
			regulator-name = "pmr735a_l6";
			regulator-min-microvolt = <480000>;
			regulator-max-microvolt = <904000>;
		};

		/* Wi-Fi/BT antenna switch 2.8 V (lahaina.dtsi:5405-5406) */
		pmr735a_l7: ldo7 {
			regulator-name = "pmr735a_l7";
			regulator-min-microvolt = <2800000>;
			regulator-max-microvolt = <2800000>;
			regulator-initial-mode = <RPMH_REGULATOR_MODE_HPM>;
			/* No consumer binding for the antenna switch: keep it on */
			regulator-always-on;
		};
	};
};

/*
 * Adreno 660. Zap shader carveout pil_gpu_mem is identical. The zap shader
 * is Razer's (vendor_b /firmware/a660_zap.mdt, squashed; docs/guvenlik-kurallari.md §8, 29 Ekim):
 * local only, never packaged. SQE/GMU firmware: firmware-qcom-adreno-a660.
 */
&gpu {
	status = "okay";
};

/*
 * No QCE driver in the kernel config: an unbound crypto node holds both
 * interconnect providers' sync_state(), so the boot-time maximum bandwidth
 * (DDR/NoC clocks) is never dropped. Safe to release only because the
 * framebuffer node votes for the MDP scanout paths (see framebuffer0).
 */
&crypto {
	status = "disabled";
};

/*
 * On together with the GPU: an enabled GMU without a bound driver would hold
 * gcc and gpucc sync_state(), so unused GDSCs (UFS, video, SF TBUs) stay on.
 */
&gmu {
	status = "okay";
};

&gpu_zap_shader {
	firmware-name = "qcom/sm8350/razer/nicole/a660_zap.mbn";
};

/*
 * PHASE 3: QUP SE13 I2C (lahaina-qupv3.dtsi:737-756, pins GPIO0/1
 * pinctrl:1440-1450). NOTE: downstream marks this SE "qcom,shared"
 * (lahaina-qupv3.dtsi:754, shared with another execution environment);
 * mainline i2c-qcom-geni has no equivalent. Clock not specified
 * downstream -> 100 kHz like sagami.
 * Expected devices (TODO(cihaz): confirm with i2cdetect on bus 13):
 *   0x0c/0x0d PM8008 "j"  (pmic-overlay:168-273; "i" @0x08/0x09 is
 *                          disabled by nicole.dtsi:166-170, and its reset
 *                          GPIO33 is listed as NC in nicole.dtsi:333-345)
 *   0x42      FSA4480     (lahaina-audio.dtsi:204-209)
 *   0x1c      NB7VPQ904M  (ONLY in lahaina-qrd.dtsi:31-65, which nicole
 *                          does NOT include -> presence unverified)
 */
&i2c13 {
	clock-frequency = <100000>;
	/* M2: on for PM8008 "j" (fan supplies); the USB-C chips below stay
	 * off until the Type-C graph is verified */
	status = "okay";

	/*
	 * PM8008 "j": mainline "qcom,pm8008" uses reg = first address and
	 * reaches the regulator block at reg+1 (0x0d) itself.
	 * Supplies: pmic-overlay:203-208 (l1/l2 S12B, l3/l4 S1C, l5-l7 BOB).
	 * Reset: GPIO35, driven high when active (pinctrl:2880-2892).
	 * TODO(cihaz): interrupt is not described downstream. On the HDK the
	 * pin pairs are 32/33 (PM8008_1 IRQ/RESET) and 34/35 (PM8008_2
	 * IRQ/RESET) (sm8350-hdk.dts gpio-line-names) -> GPIO34 assumed.
	 * Consumers: fan (vdd l7, fan l6), front camera (l1/l3/l5,
	 * camera/lahaina-camera-sensor-nicole.dtsi:14-16).
	 */
	pm8008j: pmic@c {
		compatible = "qcom,pm8008";
		reg = <0xc>;

		interrupts-extended = <&tlmm 34 IRQ_TYPE_EDGE_RISING>;
		reset-gpios = <&tlmm 35 GPIO_ACTIVE_LOW>;

		vdd-l1-l2-supply = <&pm8350_s12>;
		vdd-l3-l4-supply = <&pm8350c_s1>;
		vdd-l5-supply = <&vreg_bob>;
		vdd-l6-supply = <&vreg_bob>;
		vdd-l7-supply = <&vreg_bob>;

		pinctrl-0 = <&pm8008j_default>;
		pinctrl-names = "default";

		gpio-controller;
		#gpio-cells = <2>;
		gpio-ranges = <&pm8008j 0 0 2>;

		interrupt-controller;
		#interrupt-cells = <2>;

		#thermal-sensor-cells = <0>;

		regulators {
			/* pmic-overlay:210-217, nicole.dtsi:179-182 forces 1.2 V */
			pm8008j_l1: ldo1 {
				regulator-name = "pm8008j_l1";
				regulator-min-microvolt = <1200000>;
				regulator-max-microvolt = <1200000>;
			};

			/* pmic-overlay:219-226 */
			pm8008j_l2: ldo2 {
				regulator-name = "pm8008j_l2";
				regulator-min-microvolt = <944000>;
				regulator-max-microvolt = <1056000>;
			};

			/* pmic-overlay:228-235 */
			/* front camera vio: 1.8 V fixed, as the downstream sensor
			 * node asks (camera/lahaina-camera-sensor-nicole.dtsi:61) */
			pm8008j_l3: ldo3 {
				regulator-name = "pm8008j_l3";
				regulator-min-microvolt = <1800000>;
				regulator-max-microvolt = <1800000>;
			};

			/* pmic-overlay:237-244 */
			pm8008j_l4: ldo4 {
				regulator-name = "pm8008j_l4";
				regulator-min-microvolt = <1728000>;
				regulator-max-microvolt = <1800000>;
			};

			/* pmic-overlay:246-253 */
			/* front camera vana: 2.8 V fixed (same downstream line) */
			pm8008j_l5: ldo5 {
				regulator-name = "pm8008j_l5";
				regulator-min-microvolt = <2800000>;
				regulator-max-microvolt = <2800000>;
			};

			/* pmic-overlay:255-262 + nicole.dtsi:184-186 (max 2.9 V):
			 * fan motor supply */
			pm8008j_l6: ldo6 {
				regulator-name = "pm8008j_l6";
				regulator-min-microvolt = <2800000>;
				regulator-max-microvolt = <2900000>;
				/* mainline max31760 takes no supplies; the fan
				 * must never be unpowered (docs/guvenlik-kurallari.md) */
				regulator-always-on;
			};

			/* nicole.dtsi:188-191 (3.2-3.3 V; overrides 2.808-3.6 V
			 * of pmic-overlay:264-271): fan controller VDD */
			pm8008j_l7: ldo7 {
				regulator-name = "pm8008j_l7";
				regulator-min-microvolt = <3200000>;
				regulator-max-microvolt = <3300000>;
				regulator-always-on;
			};
		};
	};

	/*
	 * FSA4480 USB-C SBU/analog-audio switch (lahaina-audio.dtsi:204-209).
	 * Downstream gives no IRQ and no supply. TODO(cihaz): IRQ GPIO;
	 * vcc assumed BOB like sm8350-hdk.dts:417-432.
	 */
	typec-mux@42 {
		compatible = "fcs,fsa4480";
		reg = <0x42>;

		vcc-supply = <&vreg_bob>;

		mode-switch;
		orientation-switch;

		status = "okay";

		port {
			fsa4480_sbu_mux: endpoint {
				remote-endpoint = <&pmic_glink_sbu>;
			};
		};
	};

};

/*
 * Speakers: two Awinic AW88261 smart amps on QUP SE17 I2C (GPIO72/73,
 * pinctrl:1552-1564), chip ID 0x2113 read on the device (28 Oct 2026).
 * nicole.dtsi:193-223: @0x34 = channel 0 (left, IRQ GPIO90), @0x35 =
 * channel 1 (right, IRQ GPIO119); no reset line. Fed over PRI MI2S RX on
 * SD0 (nicole.dtsi:59-65: qcom,msm-mi2s-lines = <1>); SD1 carries the amps'
 * I/V feedback (TX) for Razer's ADSP speaker protection, not used here.
 * Firmware: Razer's vendor/firmware/aw882xx_acf.bin (an AW88261 ACF with
 * profiles for both channels), installed under the name below.
 * dvdd: no supply in the downstream DT; the amps answer on I2C from boot,
 * so it is an always-on 1.8 V rail. S10B is the board's 1.8 V I/O rail
 * (WCD938x, fan, WLAN I/O) -- assumption, TODO: confirm from schematics.
 */
&i2c17 {
	clock-frequency = <400000>;
	status = "okay";

	speaker_left: audio-codec@34 {
		compatible = "awinic,aw88261";
		reg = <0x34>;
		#sound-dai-cells = <0>;
		dvdd-supply = <&pm8350_s10>;
		awinic,audio-channel = <0>;
		firmware-name = "qcom/sm8350/razer/nicole/aw88261_acf.bin";
		sound-name-prefix = "Left";
	};

	speaker_right: audio-codec@35 {
		compatible = "awinic,aw88261";
		reg = <0x35>;
		#sound-dai-cells = <0>;
		dvdd-supply = <&pm8350_s10>;
		awinic,audio-channel = <1>;
		firmware-name = "qcom/sm8350/razer/nicole/aw88261_acf.bin";
		sound-name-prefix = "Right";
	};
};

&q6afedai {
	dai@16 {
		reg = <PRIMARY_MI2S_RX>;
		qcom,sd-lines = <0>;
	};
};

/ {
	/*
	 * WCD938x (lahaina-audio-overlay.dtsi:230-282): reset GPIO88, rxtx/io/buck
	 * from S10B 1.8 V, mic bias from BOB, all four mic biases 1.8 V. Register
	 * access goes over the TX SoundWire bus (wcd_tx), playback over RX (wcd_rx).
	 * nicole has no 3.5 mm jack (USB-C analog audio via FSA4480); the MBHC
	 * thresholds are the SM8450 HDK ones until that path is brought up.
	 */
	wcd938x: audio-codec {
		compatible = "qcom,wcd9380-codec";
		pinctrl-0 = <&wcd_reset_n>;
		pinctrl-names = "default";
		reset-gpios = <&tlmm 88 GPIO_ACTIVE_LOW>;

		vdd-buck-supply = <&pm8350_s10>;
		vdd-rxtx-supply = <&pm8350_s10>;
		vdd-io-supply = <&pm8350_s10>;
		vdd-mic-bias-supply = <&vreg_bob>;

		qcom,micbias1-microvolt = <1800000>;
		qcom,micbias2-microvolt = <1800000>;
		qcom,micbias3-microvolt = <1800000>;
		qcom,micbias4-microvolt = <1800000>;
		qcom,mbhc-buttons-vthreshold-microvolt = <75000 150000 237000 500000 500000 500000 500000 500000>;
		qcom,mbhc-headset-vthreshold-microvolt = <1700000>;
		qcom,mbhc-headphone-vthreshold-microvolt = <50000>;
		qcom,rx-device = <&wcd_rx>;
		qcom,tx-device = <&wcd_tx>;

		#sound-dai-cells = <1>;
	};

	sound {
		compatible = "qcom,sm8250-sndcard";
		model = "Razer-Edge";
		pinctrl-0 = <&pri_mi2s_active>;
		pinctrl-names = "default";
		/*
		 * nicole.dtsi:79-110: the digital mics are powered from WCD938x
		 * MIC BIAS1 / MIC BIAS3 (which DMIC sits on which bias is not
		 * certain, so both mics pull both), the analog mic from MIC BIAS2.
		 */
		audio-routing = "VA DMIC0", "MIC BIAS1",
				"VA DMIC0", "MIC BIAS3",
				"VA DMIC1", "MIC BIAS1",
				"VA DMIC1", "MIC BIAS3",
				"AMIC2", "MIC BIAS2",
				/* USB-C analog headset (FSA4480): RX macro -> WCD938x HPH */
				"IN1_HPHL", "HPHL_OUT",
				"IN2_HPHR", "HPHR_OUT";

		mm1-dai-link {
			link-name = "MultiMedia1";

			cpu {
				sound-dai = <&q6asmdai MSM_FRONTEND_DAI_MULTIMEDIA1>;
			};
		};

		mm2-dai-link {
			link-name = "MultiMedia2";

			cpu {
				sound-dai = <&q6asmdai MSM_FRONTEND_DAI_MULTIMEDIA2>;
			};
		};

		/* DisplayPort audio front end (hw:0,2), kept after MM1/MM2 so they keep 0 and 1 */
		mm3-dai-link {
			link-name = "MultiMedia3";

			cpu {
				sound-dai = <&q6asmdai MSM_FRONTEND_DAI_MULTIMEDIA3>;
			};
		};

		va-dai-link {
			link-name = "VA Capture";

			cpu {
				sound-dai = <&q6afedai VA_CODEC_DMA_TX_0>;
			};

			platform {
				sound-dai = <&q6routing>;
			};

			codec {
				sound-dai = <&vamacro 0>;
			};
		};

		wcd-capture-dai-link {
			link-name = "WCD Capture";

			cpu {
				sound-dai = <&q6afedai TX_CODEC_DMA_TX_3>;
			};

			platform {
				sound-dai = <&q6routing>;
			};

			codec {
				sound-dai = <&wcd938x 1>, <&swr2 0>, <&txmacro 0>;
			};
		};

		speaker-dai-link {
			link-name = "Speaker Playback";

			cpu {
				sound-dai = <&q6afedai PRIMARY_MI2S_RX>;
			};

			platform {
				sound-dai = <&q6routing>;
			};

			codec {
				sound-dai = <&speaker_left>, <&speaker_right>;
			};
		};

		/*
		 * Audio to a USB-C (DP alt mode) monitor, 1 Kasım 2026: AFE
		 * HDMI_OVER_DP_RX as on sc7180-acer-aspire1 / qcm6490-fairphone-fp5;
		 * Razer's lahaina card has the same port (lahaina-audio.dtsi:114, dai_dp).
		 */
		dp-dai-link {
			link-name = "DisplayPort Playback";

			cpu {
				sound-dai = <&q6afedai DISPLAY_PORT_RX>;
			};

			platform {
				sound-dai = <&q6routing>;
			};

			codec {
				sound-dai = <&mdss_dp>;
			};
		};

		/*
		 * USB-C analog headset (7 Nov 2026, not yet tried with an adapter):
		 * UCSI reports an audio accessory -> typec_set_mode(AUDIO) -> FSA4480
		 * puts D+/D- on HPH L/R and SBU on mic/ground, WCD938x MBHC reports
		 * the jack. Same link as sm8450-hdk/sm8550-qrd, on q6afe. Last in the
		 * node so the PCM numbers of the links above do not move.
		 */
		wcd-playback-dai-link {
			link-name = "WCD Playback";

			cpu {
				sound-dai = <&q6afedai RX_CODEC_DMA_RX_0>;
			};

			platform {
				sound-dai = <&q6routing>;
			};

			codec {
				sound-dai = <&wcd938x 0>, <&swr1 0>, <&rxmacro 0>;
			};
		};
	};
};

/*
 * Microphones, stage 1: the two digital mics (DMIC0/1, LPASS LPI GPIO6 clock /
 * GPIO7 data; lahaina-lpi.dtsi:1518-1570, nicole's Android "speaker-mic" =
 * DMIC1) through the LPASS VA macro to VA_CODEC_DMA_TX_0. On bolero 2.x the
 * DMIC clock generator lives in the VA macro, so the VA path is the one
 * mainline can drive. SM8350's LPASS digital codec is the same generation as
 * SC7280's (no VA SoundWire master, no NPL clock, codec v2.0/2.1), hence the
 * sc7280 compatible until an sm8350 one exists. Addresses/clocks: Razer
 * lahaina-audio-overlay.dtsi:27-38 and the q6afe ("Elite") clock votes.
 * Mic power: the downstream routing feeds DMIC1/2 from WCD938x MIC BIAS1/3;
 * stage 1 (VA only) recorded all zeros with the DMIC clock running (28 Oct),
 * so the bias is real: stage 2 below adds WCD938x + SoundWire.
 */
&soc {
	/*
	 * Stage 2: RX/TX macros and their SoundWire masters for WCD938x (mic
	 * bias + AMIC). Addresses/IRQs: Razer lahaina-audio-overlay.dtsi:41-75,
	 * 120-160. TX macro: SM8350 is LPASS 9.2 (new TX SMIC mux registers),
	 * which the sm8450 match data covers. SoundWire v1.6.0 as on the
	 * sibling SC7280; port tables from kodiak.dtsi. No CGCR reset provider
	 * on SM8350 yet (downstream toggles HCTL 0x032a90a0/a8), it is optional.
	 */
	/*
	 * Reset-only LPASS audio CC: the SoundWire CGCR (HW clock-gating) bits.
	 * Downstream swr-mstr clears bit 1 of HCTL 0x032a90a0 (RX) / 0x032a90a8
	 * (TX) before using the bus; SC7280/QCM6490 has the same block at the
	 * same address and offsets (0xa0/0xa8/0xb0). Without it every SoundWire
	 * read after enumeration underflowed (28 Oct). Only reg index 1 is used.
	 */
	lpass_audiocc: clock-controller@3300000 {
		compatible = "qcom,qcm6490-lpassaudiocc";
		reg = <0 0x03300000 0 0x30000>,
		      <0 0x032a9000 0 0x1000>;
		#clock-cells = <1>;
		#reset-cells = <1>;
	};

	rxmacro: codec@3200000 {
		compatible = "qcom,sm8250-lpass-rx-macro";
		reg = <0 0x03200000 0 0x1000>;
		clocks = <&q6afecc LPASS_CLK_ID_TX_CORE_MCLK LPASS_CLK_ATTRIBUTE_COUPLE_NO>,
			 <&q6afecc LPASS_CLK_ID_TX_CORE_NPL_MCLK LPASS_CLK_ATTRIBUTE_COUPLE_NO>,
			 <&q6afecc LPASS_HW_MACRO_VOTE LPASS_CLK_ATTRIBUTE_COUPLE_NO>,
			 <&q6afecc LPASS_HW_DCODEC_VOTE LPASS_CLK_ATTRIBUTE_COUPLE_NO>,
			 <&vamacro>;
		clock-names = "mclk", "npl", "macro", "dcodec", "fsgen";
		#clock-cells = <0>;
		clock-output-names = "rx-mclk";
		#sound-dai-cells = <1>;
		pinctrl-0 = <&rx_swr_active>;
		pinctrl-names = "default";
	};

	swr1: soundwire@3210000 {
		compatible = "qcom,soundwire-v1.6.0";
		reg = <0 0x03210000 0 0x2000>;
		interrupts = <GIC_SPI 155 IRQ_TYPE_LEVEL_HIGH>;
		clocks = <&rxmacro>;
		clock-names = "iface";
		label = "RX";
		resets = <&lpass_audiocc LPASS_AUDIO_SWR_RX_CGCR>;
		reset-names = "swr_audio_cgcr";

		qcom,din-ports = <0>;
		qcom,dout-ports = <5>;
		qcom,ports-word-length =	/bits/ 8 <0x01 0x07 0x04 0xff 0xff>;
		qcom,ports-sinterval-low =	/bits/ 8 <0x03 0x3f 0x1f 0x03 0x03>;
		qcom,ports-offset1 =		/bits/ 8 <0x00 0x00 0x0b 0x01 0x01>;
		qcom,ports-offset2 =		/bits/ 8 <0x00 0x00 0x0b 0x00 0x00>;
		qcom,ports-lane-control =	/bits/ 8 <0x01 0x00 0x00 0x00 0x00>;
		qcom,ports-block-pack-mode =	/bits/ 8 <0xff 0x00 0x01 0xff 0xff>;
		qcom,ports-hstart =		/bits/ 8 <0xff 0x03 0xff 0xff 0xff>;
		qcom,ports-hstop =		/bits/ 8 <0xff 0x06 0xff 0xff 0xff>;
		qcom,ports-block-group-count =	/bits/ 8 <0xff 0xff 0xff 0xff 0x00>;

		#sound-dai-cells = <1>;
		#address-cells = <2>;
		#size-cells = <0>;

		/* downstream wcd938x-rx-slave reg <0x0D 0x01170224> */
		wcd_rx: codec@0,4 {
			compatible = "sdw20217010d00";
			reg = <0 4>;
			qcom,rx-port-mapping = <1 2 3 4 5>;
		};
	};

	txmacro: codec@3220000 {
		compatible = "qcom,sm8450-lpass-tx-macro";
		reg = <0 0x03220000 0 0x1000>;
		clocks = <&q6afecc LPASS_CLK_ID_TX_CORE_MCLK LPASS_CLK_ATTRIBUTE_COUPLE_NO>,
			 <&q6afecc LPASS_CLK_ID_TX_CORE_NPL_MCLK LPASS_CLK_ATTRIBUTE_COUPLE_NO>,
			 <&q6afecc LPASS_HW_MACRO_VOTE LPASS_CLK_ATTRIBUTE_COUPLE_NO>,
			 <&q6afecc LPASS_HW_DCODEC_VOTE LPASS_CLK_ATTRIBUTE_COUPLE_NO>,
			 <&vamacro>;
		clock-names = "mclk", "npl", "macro", "dcodec", "fsgen";
		#clock-cells = <0>;
		clock-output-names = "tx-mclk";
		#sound-dai-cells = <1>;
		pinctrl-0 = <&tx_swr_active>;
		pinctrl-names = "default";
	};

	swr2: soundwire@3230000 {
		compatible = "qcom,soundwire-v1.6.0";
		reg = <0 0x03230000 0 0x2000>;
		interrupts = <GIC_SPI 166 IRQ_TYPE_LEVEL_HIGH>;
		clocks = <&txmacro>;
		clock-names = "iface";
		label = "TX";
		resets = <&lpass_audiocc LPASS_AUDIO_SWR_TX_CGCR>;
		reset-names = "swr_audio_cgcr";

		qcom,din-ports = <3>;
		qcom,dout-ports = <0>;
		qcom,ports-sinterval-low =	/bits/ 8 <0x01 0x03 0x03>;
		qcom,ports-offset1 =		/bits/ 8 <0x01 0x00 0x02>;
		qcom,ports-offset2 =		/bits/ 8 <0x00 0x00 0x00>;
		qcom,ports-hstart =		/bits/ 8 <0xff 0xff 0xff>;
		qcom,ports-hstop =		/bits/ 8 <0xff 0xff 0xff>;
		qcom,ports-word-length =	/bits/ 8 <0xff 0x00 0xff>;
		qcom,ports-block-pack-mode =	/bits/ 8 <0xff 0xff 0xff>;
		qcom,ports-block-group-count =	/bits/ 8 <0xff 0xff 0xff>;
		qcom,ports-lane-control =	/bits/ 8 <0x00 0x01 0x00>;

		#sound-dai-cells = <1>;
		#address-cells = <2>;
		#size-cells = <0>;

		/* downstream wcd938x-tx-slave reg <0x0D 0x01170223>, tx_swr_ch_map */
		wcd_tx: codec@0,3 {
			compatible = "sdw20217010d00";
			reg = <0 3>;
			qcom,tx-port-mapping = <1 1 2 3>;
		};
	};

	vamacro: codec@3370000 {
		compatible = "qcom,sc7280-lpass-va-macro";
		reg = <0 0x03370000 0 0x1000>;
		clocks = <&q6afecc LPASS_CLK_ID_TX_CORE_MCLK LPASS_CLK_ATTRIBUTE_COUPLE_NO>,
			 <&q6afecc LPASS_HW_MACRO_VOTE LPASS_CLK_ATTRIBUTE_COUPLE_NO>,
			 <&q6afecc LPASS_HW_DCODEC_VOTE LPASS_CLK_ATTRIBUTE_COUPLE_NO>;
		clock-names = "mclk", "macro", "dcodec";
		#clock-cells = <0>;
		clock-output-names = "fsgen";
		#sound-dai-cells = <1>;
		pinctrl-0 = <&dmic01_active>;
		pinctrl-names = "default";
		/* Android's TX-path DMIC rate (lahaina-audio-overlay.dtsi:48) */
		qcom,dmic-sample-rate = <2400000>;
	};
};

&lpass_tlmm {
	/* lahaina-lpi.dtsi:1336-1500 */
	tx_swr_active: tx-swr-active-state {
		clk-pins {
			pins = "gpio0";
			function = "swr_tx_clk";
			drive-strength = <4>;
			slew-rate = <1>;
			bias-disable;
		};

		data-pins {
			pins = "gpio1", "gpio2", "gpio14";
			function = "swr_tx_data";
			drive-strength = <4>;
			slew-rate = <1>;
			bias-bus-hold;
		};
	};

	rx_swr_active: rx-swr-active-state {
		clk-pins {
			pins = "gpio3";
			function = "swr_rx_clk";
			drive-strength = <2>;
			slew-rate = <1>;
			bias-disable;
		};

		data-pins {
			pins = "gpio4", "gpio5";
			function = "swr_rx_data";
			drive-strength = <2>;
			slew-rate = <1>;
			bias-bus-hold;
		};
	};

	dmic01_active: dmic01-active-state {
		clk-pins {
			pins = "gpio6";
			function = "dmic1_clk";
			drive-strength = <8>;
			output-high;
		};

		data-pins {
			pins = "gpio7";
			function = "dmic1_data";
			drive-strength = <8>;
		};
	};
};

/*
 * Haptics, QUP SE19 I2C (GPIO76/77, pinctrl:1580-1592).
 * nicole.dtsi:225-262: Awinic AW8622x ("awinic,haptic_nv") @0x5a, the
 * AW862xx answering at 0x58, IRQ GPIO44, reset GPIO106, GPIO16/17 kept
 * hi-Z. Mainline aw86927 does not cover AW8622x (register map differs at
 * 0x2d/0x2e and 0x48): our drivers/haptics/aw8622x.c (continuous mode),
 * proven from user space (i2c-dev) first, 30 Ekim.
 */
&i2c19 {
	clock-frequency = <400000>;
	status = "okay";

	/*
	 * No reset-gpios on purpose: the chip comes up with Razer's continuous
	 * mode tuning in place and the first tests (30 Ekim) ran in that state;
	 * a reset pulse would put the CONTCFG registers back to chip defaults.
	 * The IRQ (GPIO44) is not used in continuous mode.
	 */
	haptics@58 {
		compatible = "awinic,aw8622x";
		reg = <0x58>;
	};
};

/*
 * PHASE 3: display. Downstream: DSI0 only (nicole.dtsi:569-575), panel
 * Visionox VTDR6130 1080x2400 DSC, command mode, 4 lanes,
 * reset GPIO24 (lahaina-sde-display-qrd.dtsi:206), TE GPIO82
 * (lahaina-sde-display-qrd.dtsi:207, mdp_vsync pinctrl:3056-3067).
 * Mainline panel-visionox-vtdr6130.c uses VIDEO mode and a different
 * init sequence than Razer's (panel dtsi:69-130) -> nicole variant in
 * drivers/panel/. Works since 2026-10-29 (DPU 7.0, DSC, command mode, TE).
 */
&mdss {
	status = "okay";
};

/*
 * dispcc reprograms the display PLLs at probe, which kills the picture ABL
 * left running (2026-10-25: green flash, then black). Since 2026-10-29 msm
 * DRM + the vtdr6130 nicole panel variant take over (simpledrm until then).
 */
&dispcc {
	status = "okay";
};

&mdss_dsi0 {
	vdda-supply = <&pm8350_l6>;	/* display/lahaina-sde.dtsi:90 vdda-1p2 = L6B */
	status = "okay";

	panel@0 {
		/* drivers/panel/0001-drm-panel-visionox-vtdr6130-razer-nicole.patch */
		compatible = "visionox,vtdr6130-razer-nicole";
		reg = <0>;

		pinctrl-0 = <&sde_dsi_active>, <&sde_te_active>;
		pinctrl-1 = <&sde_dsi_suspend>, <&sde_te_active>;
		pinctrl-names = "default", "sleep";

		/*
		 * Supplies (nicole variant of the binding, see patch):
		 *  vddio = L12C (sde-display.dtsi:98, 1.86 V nicole.dtsi:302-305)
		 *  vci   = L13C (downstream "vdd" 3.0 V, sde-display.dtsi:99)
		 *  avdd  = downstream "avdd" GPIO13 switch (nicole.dtsi:295-316).
		 *          No separate 1.2 V "vdd" rail on nicole, unlike sm8550-qrd.
		 *          TODO(cihaz): confirm which rail GPIO13 really switches.
		 */
		vddio-supply = <&pm8350c_l12>;
		vci-supply = <&pm8350c_l13>;
		avdd-supply = <&panel_avdd>;

		reset-gpios = <&tlmm 24 GPIO_ACTIVE_LOW>;

		/*
		 * panel dtsi:40 qcom,mdss-dsi-panel-orientation = "180". Kept as the
		 * truth about the hardware, but the device cmdline overrides it with
		 * video=DSI-1:panel_orientation=normal: from this property the fbdev
		 * console put a 180° rotation on its plane (plane-0), and sway never
		 * clears it. The panel looked upright only while it scanned out of
		 * plane-0; when DP took crtc-0 first, the panel turned upside down
		 * (1 Kasım). Now sway alone rotates (transforms in device-razer-nicole).
		 */
		rotation = <180>;

		port {
			panel0_in: endpoint {
				remote-endpoint = <&mdss_dsi0_out>;
			};
		};
	};
};

&mdss_dsi0_out {
	remote-endpoint = <&panel0_in>;
	data-lanes = <0 1 2 3>;
	/* Command mode, TE on GPIO82 (mdp_vsync), see docs/panel-analizi.md */
	qcom,te-source = "mdp_vsync_p";
};

&mdss_dsi0_phy {
	/*
	 * lahaina-sde.dtsi:91 says L1B, but :267 overrides mdss_dsi_phy0
	 * vdda-0p9-supply = <&L5B>, which is what nicole uses.
	 */
	vdds-supply = <&pm8350_l5>;
	status = "okay";
};

/*
 * PHASE 3: QCA6490 on PCIe0 (cnss qcom,wlan-rc-num = <0>,
 * lahaina.dtsi:5386). PERST 94, CLKREQ 95, WAKE 96 (pinctrl:2895-2930,
 * lahaina-pcie.dtsi:38-39). PCIe supplies L5B/L6B (lahaina-pcie.dtsi:49-50).
 */
&pcie0 {
	perst-gpios = <&tlmm 94 GPIO_ACTIVE_LOW>;
	wake-gpios = <&tlmm 96 GPIO_ACTIVE_HIGH>;

	pinctrl-0 = <&pcie0_default_state>;
	pinctrl-names = "default";

	/* mainline sm8350.dtsi has no paths here; same NoC-stall risk as MDP/SDHC */
	interconnects = <&aggre2_noc MASTER_PCIE_0 0 &mc_virt SLAVE_EBI1 0>,
			<&gem_noc MASTER_APPSS_PROC 0 &config_noc SLAVE_PCIE_0 0>;
	interconnect-names = "pcie-mem", "cpu-pcie";

	status = "okay";

	pcie@0 {
		/* QCA6490 enumerates as WCN6855 hw2.1 (ath11k pci.c 0x1103).
		 * TODO(cihaz): confirm PCI ID with lspci/sysfs on Android. */
		wifi@0 {
			compatible = "pci17cb,1103";
			reg = <0x10000 0x0 0x0 0x0 0x0>;

			vddrfacmn-supply = <&vreg_pmu_rfa_cmn_0p8>;
			vddaon-supply = <&vreg_pmu_aon_0p8>;
			vddwlcx-supply = <&vreg_pmu_wlcx_0p8>;
			vddwlmx-supply = <&vreg_pmu_wlmx_0p8>;
			vddpcie1p8-supply = <&vreg_pmu_pcie_1p8>;
			vddpcie0p9-supply = <&vreg_pmu_pcie_0p9>;
			vddrfa0p8-supply = <&vreg_pmu_rfa_0p8>;
			vddrfa1p2-supply = <&vreg_pmu_rfa_1p2>;
			vddrfa1p8-supply = <&vreg_pmu_rfa_1p7>;
		};
	};
};

&pcie0_phy {
	vdda-phy-supply = <&pm8350_l5>;
	vdda-pll-supply = <&pm8350_l6>;
	status = "okay";
};

/*
 * pcie1 stays disabled: downstream it carries wil6210 (qrd-common:224-226,
 * lahaina.dtsi:5662-5664) or, on the 5G SKU, probably the Quectel modem.
 * nicole only tweaks it (nicole.dtsi:981-984). TODO(cihaz): lspci.
 */

&pm8350_gpios {
	/* pmic-overlay:12-19 */
	vol_up_n: vol-up-n-state {
		pins = "gpio6";
		function = "normal";
		power-source = <1>;
		bias-pull-up;
		input-enable;
	};

	/* pmic-overlay:22-29 (used by joystick_usb_vbus, PHASE 3) */
	joystick_vbus_en: joystick-vbus-en-state {
		pins = "gpio8";
		function = "normal";
		power-source = <0>;
		output-low;
	};
};

/*
 * Read-only ADC channels, enabled in phase 2 so that board temperatures
 * can be logged (docs/guvenlik-kurallari.md section 3). Channels and labels from
 * pmic-overlay:285-361 and nicole.dtsi:608-616.
 */
&pmk8350_vadc {
	channel@44 {
		reg = <PMK8350_ADC7_AMUX_THM1_100K_PU>;
		qcom,ratiometric;
		qcom,hw-settle-time = <200>;
		qcom,pre-scaling = <1 1>;
		label = "pmk8350_xo_therm";
	};

	channel@144 {
		reg = <PM8350_ADC7_AMUX_THM1_100K_PU(1)>;
		qcom,ratiometric;
		qcom,hw-settle-time = <200>;
		qcom,pre-scaling = <1 1>;
		label = "pm8350_msm_therm";
	};

	/* "quiet therm" used by the fan zone quiet-therm-step
	 * (nicole.dtsi:835-909) */
	channel@145 {
		reg = <PM8350_ADC7_AMUX_THM2_100K_PU(1)>;
		qcom,ratiometric;
		qcom,hw-settle-time = <200>;
		qcom,pre-scaling = <1 1>;
		label = "pm8350_quiet_therm";
	};

	channel@147 {
		reg = <PM8350_ADC7_AMUX_THM4_100K_PU(1)>;
		qcom,ratiometric;
		qcom,hw-settle-time = <200>;
		qcom,pre-scaling = <1 1>;
		label = "pm8350_wide_rfc_therm";
	};

	channel@148 {
		reg = <PM8350_ADC7_AMUX_THM5_100K_PU(1)>;
		qcom,ratiometric;
		qcom,hw-settle-time = <200>;
		qcom,pre-scaling = <1 1>;
		label = "pm8350_rear_tof_therm";
	};

	/* nicole.dtsi:608-616 */
	channel@346 {
		reg = <PM8350B_ADC7_AMUX_THM3_100K_PU>;
		qcom,ratiometric;
		qcom,hw-settle-time = <200>;
		qcom,pre-scaling = <1 1>;
		label = "pm8350b_smb_temp_therm";
	};

	channel@347 {
		reg = <PM8350B_ADC7_AMUX_THM4_100K_PU>;
		qcom,ratiometric;
		qcom,hw-settle-time = <200>;
		qcom,pre-scaling = <1 1>;
		label = "pm8350b_usb_conn_therm";
	};
};

/* PHASE 3: ADC thermal monitor for the fan "quiet" zone */
&pmk8350_adc_tm {
	status = "disabled";

	quiet-therm@0 {
		reg = <0>;
		io-channels = <&pmk8350_vadc PM8350_ADC7_AMUX_THM2_100K_PU(1)>;
		qcom,ratiometric;
		qcom,hw-settle-time-us = <200>;
	};
};

&pmk8350_rtc {
	status = "okay";
};

/* Power key: PON kpdpwr (Razer pmk8350.dtsi:30-42) */
&pon_pwrkey {
	status = "okay";
};

/* Volume down: PON RESIN (Razer pmk8350.dtsi:44-47) */
&pon_resin {
	linux,code = <KEY_VOLUMEDOWN>;
	status = "okay";
};

/* QUP wrapper 0 holds uart2 (debug UART, SE3) */
&qupv3_id_0 {
	status = "okay";
};

/* PHASE 3: wrapper 1 = spi12 (touch), i2c13 (PM8008/FSA4480/redriver) */
&qupv3_id_1 {
	status = "okay";
};

/* wrapper 2 = i2c17 (amps, on), i2c19 (haptics), uart18 (BT) */
&qupv3_id_2 {
	status = "okay";
};

/*
 * microSD = phase-2 rootfs.
 * nicole.dtsi:286-293: cd-gpios GPIO80 ACTIVE_HIGH (overrides GPIO92
 * ACTIVE_LOW of qrd-common:53). Supplies qrd-common:40-47.
 * TODO(cihaz): verify CD polarity (gpioinfo / card insert); if wrong,
 * flip the flag or temporarily use broken-cd.
 */
/*
 * sdhci-msm votes its interconnect paths through the OPP table, but the
 * sm8350.dtsi OPPs carry no bandwidth, so the SD card (our root fs) has no
 * vote at all: once the interconnect providers reach sync_state() the
 * aggre2 path (BCM SN8, not keepalive) drops to 0 and root fs I/O stalls.
 * Values from Razer's downstream lahaina.dtsi:3199-3214 msm-bus vectors
 * (ab = avg, ib = peak; sdhc-ddr, cpu-sdhc): 100 MB/s and 200 MB/s cases.
 */
&sdhc2_opp_table {
	opp-100000000 {
		opp-peak-kBps = <200000 150000>;
		opp-avg-kBps = <261438 150000>;
	};

	opp-202000000 {
		opp-peak-kBps = <400000 300000>;
		opp-avg-kBps = <261438 300000>;
	};
};

&sdhc_2 {
	cd-gpios = <&tlmm 80 GPIO_ACTIVE_HIGH>;

	pinctrl-0 = <&sdc2_default_state>, <&sdc2_card_det_n>;
	pinctrl-1 = <&sdc2_sleep_state>, <&sdc2_card_det_sleep>;
	pinctrl-names = "default", "sleep";

	vmmc-supply = <&pm8350c_l9>;
	vqmmc-supply = <&pm8350c_l6>;

	no-sdio;
	no-mmc;

	/*
	 * DLL settings: Razer qcom,dll-hsr-list (lahaina.dtsi:3233) dll_config /
	 * ddr_config, same as mainline sm8250. Missing in mainline sm8350.dtsi; without
	 * them SDR104 (202 MHz) writes corrupted the first ~250 MB of the pmOS image on
	 * the card with no host error, reads then differed on every pass (2026-10-25).
	 */
	qcom,dll-config = <0x0007642c>;
	qcom,ddr-config = <0x80040868>;
	/*
	 * With these, SDR104 at 202 MHz passed scripts/lab/cihazda/sd-stres.sh twice
	 * (1 GiB random + 300 MiB zeros, uncached re-reads; 44 MB/s write, 64 MB/s read).
	 */

	status = "okay";
};

/* Razer drive strengths: cmd/data 10 mA (pinctrl:106-116, mainline 16) */
&sdc2_default_state {
	cmd-pins {
		drive-strength = <10>;
	};

	data-pins {
		drive-strength = <10>;
	};
};

/*
 * PHASE 3: touchscreen. nicole.dtsi:141-164: FocalTech FTS (FT3658S)
 * on qupv3_se12_spi (= mainline spi12 @a90000), CS0, 6 MHz,
 * IRQ GPIO23 (0x2008 = falling | oneshot), reset GPIO22,
 * vdd L3C, vcc_i2c L8C, 10 touches, 1080x2400.
 * Driver: drivers/touchscreen/focaltech_ft3658s_spi.c (own, from Razer's vendor driver).
 */
&spi12 {
	pinctrl-0 = <&qup_spi12_default>;
	pinctrl-names = "default";

	status = "okay";

	touchscreen@0 {
		compatible = "focaltech,ft3658s";
		reg = <0>;
		spi-max-frequency = <6000000>;

		interrupts-extended = <&tlmm 23 IRQ_TYPE_EDGE_FALLING>;
		reset-gpios = <&tlmm 22 GPIO_ACTIVE_LOW>;

		vdd-supply = <&pm8350c_l3>;
		iovdd-supply = <&pm8350c_l8>;

		pinctrl-0 = <&ts_active>;
		pinctrl-names = "default";

		touchscreen-size-x = <1080>;
		touchscreen-size-y = <2400>;
		/*
		 * The digitizer reports in the panel's own scanout coordinates, so
		 * no inversion: the compositor's output transform turns touch with
		 * the picture. (Until 1 Kasım touchscreen-inverted-x/y were set; they
		 * only made up for the console's leftover plane rotation, see the
		 * panel node.)
		 */
	};
};

&thermal_zones {
	/*
	 * PHASE 3 fan hooks. The cooling maps reference &fancontroller,
	 * which is disabled and (in mainline) not a cooling device yet,
	 * so they are inert in phase 2.
	 * Razer zone -> mainline zone mapping (same tsens channel):
	 *   cpu-1-6-step  tsens0 13 (lahaina-thermal.dtsi:546) -> cpu6-bottom
	 *   cpu-1-7-step  tsens0 14 (lahaina-thermal.dtsi:584) -> cpu7-bottom
	 *   gpuss-0-step  tsens1 1  (lahaina-thermal.dtsi:623) -> gpu-top
	 *   gpuss-1-step  tsens1 2  (lahaina-thermal.dtsi:645) -> gpu-bottom
	 *   video-step    tsens1 6  (nicole.dtsi:779)          -> video
	 * Trip points and fan levels from nicole.dtsi:618-794.
	 */
	cpu6-bottom-thermal {
		trips {
			cpu6_bottom_fan0: fan-trip0 {
				temperature = <80000>;
				hysteresis = <5000>;
				type = "passive";
			};

			cpu6_bottom_fan1: fan-trip1 {
				temperature = <90000>;
				hysteresis = <5000>;
				type = "passive";
			};

			cpu6_bottom_fan2: fan-trip2 {
				temperature = <95000>;
				hysteresis = <5000>;
				type = "passive";
			};
		};

		cooling-maps {
			map-fan0 {
				trip = <&cpu6_bottom_fan0>;
				cooling-device = <&fancontroller 5 5>;
			};

			map-fan1 {
				trip = <&cpu6_bottom_fan1>;
				cooling-device = <&fancontroller 6 6>;
			};

			map-fan2 {
				trip = <&cpu6_bottom_fan2>;
				cooling-device = <&fancontroller 7 7>;
			};
		};
	};

	cpu7-bottom-thermal {
		trips {
			cpu7_bottom_fan0: fan-trip0 {
				temperature = <80000>;
				hysteresis = <5000>;
				type = "passive";
			};

			cpu7_bottom_fan1: fan-trip1 {
				temperature = <90000>;
				hysteresis = <5000>;
				type = "passive";
			};

			cpu7_bottom_fan2: fan-trip2 {
				temperature = <95000>;
				hysteresis = <5000>;
				type = "passive";
			};
		};

		cooling-maps {
			map-fan0 {
				trip = <&cpu7_bottom_fan0>;
				cooling-device = <&fancontroller 5 5>;
			};

			map-fan1 {
				trip = <&cpu7_bottom_fan1>;
				cooling-device = <&fancontroller 6 6>;
			};

			map-fan2 {
				trip = <&cpu7_bottom_fan2>;
				cooling-device = <&fancontroller 7 7>;
			};
		};
	};

	gpu-top-thermal {
		trips {
			gpu_top_fan0: fan-trip0 {
				temperature = <85000>;
				hysteresis = <5000>;
				type = "passive";
			};

			gpu_top_fan1: fan-trip1 {
				temperature = <90000>;
				hysteresis = <5000>;
				type = "passive";
			};

			gpu_top_fan2: fan-trip2 {
				temperature = <95000>;
				hysteresis = <0>;
				type = "passive";
			};
		};

		cooling-maps {
			map-fan0 {
				trip = <&gpu_top_fan0>;
				cooling-device = <&fancontroller 5 5>;
			};

			map-fan1 {
				trip = <&gpu_top_fan1>;
				cooling-device = <&fancontroller 6 6>;
			};

			map-fan2 {
				trip = <&gpu_top_fan2>;
				cooling-device = <&fancontroller 7 7>;
			};
		};
	};

	gpu-bottom-thermal {
		trips {
			gpu_bottom_fan0: fan-trip0 {
				temperature = <85000>;
				hysteresis = <5000>;
				type = "passive";
			};

			gpu_bottom_fan1: fan-trip1 {
				temperature = <90000>;
				hysteresis = <5000>;
				type = "passive";
			};

			gpu_bottom_fan2: fan-trip2 {
				temperature = <95000>;
				hysteresis = <0>;
				type = "passive";
			};
		};

		cooling-maps {
			map-fan0 {
				trip = <&gpu_bottom_fan0>;
				cooling-device = <&fancontroller 5 5>;
			};

			map-fan1 {
				trip = <&gpu_bottom_fan1>;
				cooling-device = <&fancontroller 6 6>;
			};

			map-fan2 {
				trip = <&gpu_bottom_fan2>;
				cooling-device = <&fancontroller 7 7>;
			};
		};
	};

	video-thermal {
		trips {
			video_fan0: fan-trip0 {
				temperature = <90000>;
				hysteresis = <2000>;
				type = "passive";
			};
		};

		cooling-maps {
			map-fan0 {
				trip = <&video_fan0>;
				cooling-device = <&fancontroller 7 7>;
			};
		};
	};

	/*
	 * PHASE 3: skin ("quiet") zone, nicole.dtsi:835-909:
	 * 32/34/36/38/40/42 C (hyst 2 C) -> fan levels 2..7.
	 */
	quiet-thermal {
		polling-delay-passive = <0>;
		thermal-sensors = <&pmk8350_adc_tm 0>;
		status = "disabled";

		trips {
			quiet_fan0: fan-trip0 {
				temperature = <32000>;
				hysteresis = <2000>;
				type = "passive";
			};

			quiet_fan1: fan-trip1 {
				temperature = <34000>;
				hysteresis = <2000>;
				type = "passive";
			};

			quiet_fan2: fan-trip2 {
				temperature = <36000>;
				hysteresis = <2000>;
				type = "passive";
			};

			quiet_fan3: fan-trip3 {
				temperature = <38000>;
				hysteresis = <2000>;
				type = "passive";
			};

			quiet_fan4: fan-trip4 {
				temperature = <40000>;
				hysteresis = <2000>;
				type = "passive";
			};

			quiet_fan5: fan-trip5 {
				temperature = <42000>;
				hysteresis = <2000>;
				type = "passive";
			};
		};

		cooling-maps {
			map-fan0 {
				trip = <&quiet_fan0>;
				cooling-device = <&fancontroller 2 2>;
			};

			map-fan1 {
				trip = <&quiet_fan1>;
				cooling-device = <&fancontroller 3 3>;
			};

			map-fan2 {
				trip = <&quiet_fan2>;
				cooling-device = <&fancontroller 4 4>;
			};

			map-fan3 {
				trip = <&quiet_fan3>;
				cooling-device = <&fancontroller 5 5>;
			};

			map-fan4 {
				trip = <&quiet_fan4>;
				cooling-device = <&fancontroller 6 6>;
			};

			map-fan5 {
				trip = <&quiet_fan5>;
				cooling-device = <&fancontroller 7 7>;
			};
		};
	};
};

/*
 * No APSS watchdog node: under the Gunyah hypervisor the APSS WDT at
 * 0x17c10000 belongs to the hypervisor and an EL1 access aborts. With the
 * node, qcom_wdt_probe() crashed PID 1 at 0.37 s ("Attempted to kill init",
 * photographed 2026-10-25, lab log). Android uses the hypervisor's
 * virtual watchdog instead (/hypervisor/qcom,hh-watchdog in the live DT,
 * added by Gunyah's DTBO) -> Gunyah watchdog driver, later.
 */

/*
 * Front camera, stage 1 (6 Kasım): camera clock controller, CCI1 and the Hi-556 sensor.
 * Razer: lahaina.dtsi:2396-2407 (camcc), camera/lahaina-camera.dtsi (cci1: 0xac50000,
 * SPI 271, cci3 pins 113/114 pulled up), camera/lahaina-camera-sensor-nicole.dtsi
 * (sensor on cci1 master 1, MCLK5 = GPIO105 at 19.2 MHz, reset GPIO115, vio L3 1.8 V,
 * vana L5 2.8 V, vdig L1 1.2 V, CSIPHY5, roll 270). Address 0x20 (8-bit 0x40) and chip ID
 * 0x556 from Android's log (yedek/bugreport: "slave_addr:0x40,sensor_id:0x556").
 * The CSI-2 endpoint has no remote yet: CAMSS for SM8350 is stage 2.
 */
&soc {
	camcc: clock-controller@ad00000 {
		compatible = "qcom,sm8350-camcc";
		reg = <0 0x0ad00000 0 0x10000>;
		clocks = <&rpmhcc RPMH_CXO_CLK>,
			 <&rpmhcc RPMH_CXO_CLK_A>,
			 <&sleep_clk>;
		/* Zapolskiy's camcc v2 binding: CAM_CC_PLL0 at 1200 MHz needs MX at SVS_L1 */
		power-domains = <&rpmhpd RPMHPD_MMCX>,
				<&rpmhpd RPMHPD_MX>;
		required-opps = <&rpmhpd_opp_low_svs>,
				<&rpmhpd_opp_svs_l1>;
		#clock-cells = <1>;
		#reset-cells = <1>;
		#power-domain-cells = <1>;
	};

	cci1: cci@ac50000 {
		compatible = "qcom,sm8350-cci", "qcom,msm8996-cci";
		#address-cells = <1>;
		#size-cells = <0>;

		reg = <0 0x0ac50000 0 0x1000>;
		interrupts = <GIC_SPI 271 IRQ_TYPE_EDGE_RISING>;
		power-domains = <&camcc TITAN_TOP_GDSC>;

		clocks = <&camcc CAM_CC_CAMNOC_AXI_CLK>,
			 <&camcc CAM_CC_SLOW_AHB_CLK_SRC>,
			 <&camcc CAM_CC_CPAS_AHB_CLK>,
			 <&camcc CAM_CC_CCI_1_CLK>,
			 <&camcc CAM_CC_CCI_1_CLK_SRC>;
		clock-names = "camnoc_axi",
			      "slow_ahb_src",
			      "cpas_ahb",
			      "cci",
			      "cci_src";
		assigned-clocks = <&camcc CAM_CC_CCI_1_CLK_SRC>;
		assigned-clock-rates = <37500000>;

		pinctrl-0 = <&cci1_i2c1_default>;
		pinctrl-1 = <&cci1_i2c1_sleep>;
		pinctrl-names = "default", "sleep";

		cci1_i2c1: i2c-bus@1 {
			reg = <1>;
			clock-frequency = <400000>;
			#address-cells = <1>;
			#size-cells = <0>;

			camera@20 {
				compatible = "hynix,hi556";
				reg = <0x20>;

				clocks = <&camcc CAM_CC_MCLK5_CLK>;
				assigned-clocks = <&camcc CAM_CC_MCLK5_CLK>;
				assigned-clock-rates = <19200000>;

				dovdd-supply = <&pm8008j_l3>;
				avdd-supply = <&pm8008j_l5>;
				dvdd-supply = <&pm8008j_l1>;
				reset-gpios = <&tlmm 115 GPIO_ACTIVE_LOW>;

				pinctrl-0 = <&cam_mclk5_default &cam_rst5_default>;
				pinctrl-names = "default";

				orientation = <0>;	/* front */
				rotation = <270>;

				port {
					hi556_ep: endpoint {
						data-lanes = <1 2>;
						link-frequencies = /bits/ 64 <437000000>;
					};
				};
			};
		};
	};
};

&tlmm {
	/*
	 * TZ-protected GPIOs. Razer's downstream pinctrl driver reserves
	 * only 56-59 for nicole (drivers/pinctrl/qcom/pinctrl-lahaina.c:1940-
	 * 1946, "#ifdef CONFIG_MACH_RAZER_NICOLE"). Do NOT copy the HDK's
	 * <52 8>: GPIO52-55 are the touch SPI on nicole.
	 */
	gpio-reserved-ranges = <56 4>;

	/*
	 * Names inferred from the Razer DT (no schematic). Straps:
	 * sku = GPIO7:6:3 (MSB..LSB), 0 = 5G, else Wi-Fi; board_rev =
	 * GPIO51:50:45, 7 = MP (nicole.dtsi:555-566,
	 * drivers/misc/thundersoft_straps.c:28-90).
	 */
	gpio-line-names = "PM8008_I2C_SDA", /* GPIO_0 */
			  "PM8008_I2C_SCL",
			  "",
			  "SKU_STRAP_0",
			  "",
			  "",
			  "SKU_STRAP_1",
			  "SKU_STRAP_2",
			  "FAN_I2C_SDA",
			  "FAN_I2C_SCL",
			  "", /* GPIO_10 */
			  "",
			  "NC",
			  "DISP_AVDD_EN_N",
			  "",
			  "",
			  "HAP_HIZ_0",
			  "HAP_HIZ_1",
			  "DEBUG_UART_0",
			  "DEBUG_UART_1",
			  "", /* GPIO_20 */
			  "",
			  "TS_RESET_N",
			  "TS_INT_N",
			  "DISP_RESET_N",
			  "",
			  "NC",
			  "",
			  "",
			  "",
			  "", /* GPIO_30 */
			  "",
			  "",
			  "NC",
			  "",
			  "PM8008J_RESET_N",
			  "",
			  "",
			  "",
			  "",
			  "", /* GPIO_40 */
			  "",
			  "",
			  "",
			  "HAP_INT_N",
			  "BOARD_REV_STRAP_0",
			  "",
			  "",
			  "USB_OCP_CTRL",
			  "5G_MODULE_PWR_OFF",
			  "BOARD_REV_STRAP_1", /* GPIO_50 */
			  "BOARD_REV_STRAP_2",
			  "TS_SPI_MISO",
			  "TS_SPI_MOSI",
			  "TS_SPI_CLK",
			  "TS_SPI_CS_N",
			  "RESERVED_TZ",
			  "RESERVED_TZ",
			  "RESERVED_TZ",
			  "RESERVED_TZ",
			  "", /* GPIO_60 */
			  "",
			  "",
			  "",
			  "WLAN_EN",
			  "BT_EN",
			  "",
			  "",
			  "BT_UART_CTS",
			  "BT_UART_RFR",
			  "BT_UART_TX", /* GPIO_70 */
			  "BT_UART_RX",
			  "SPK_AMP_I2C_SDA",
			  "SPK_AMP_I2C_SCL",
			  "",
			  "",
			  "HAP_I2C_SDA",
			  "HAP_I2C_SCL",
			  "FAN_USB_CHARGE_EN",
			  "USB_OCP_INT_N",
			  "SD_CARD_DET", /* GPIO_80 */
			  "USB_PHY_PS",
			  "DISP_TE",
			  "",
			  "",
			  "",
			  "SIM_GPIO",
			  "",
			  "WCD_RESET_N",
			  "",
			  "SPK_AMP_L_INT", /* GPIO_90 */
			  "",
			  "",
			  "FAN_DPR_EN",
			  "PCIE0_RESET_N",
			  "PCIE0_CLK_REQ_N",
			  "PCIE0_WAKE_N",
			  "PCIE1_RESET_N",
			  "PCIE1_CLK_REQ_N",
			  "PCIE1_WAKE_N",
			  "", /* GPIO_100 */
			  "",
			  "",
			  "",
			  "",
			  "CAM_MCLK5",
			  "HAP_RESET_N",
			  "",
			  "",
			  "",
			  "", /* GPIO_110 */
			  "",
			  "",
			  "",
			  "",
			  "CAM5_RESET_N",
			  "5G_MODULE_RESET",
			  "",
			  "",
			  "SPK_AMP_R_INT",
			  "", /* GPIO_120 */
			  "",
			  "",
			  "",
			  "",
			  "PRI_MI2S_SCK",
			  "PRI_MI2S_SD0",
			  "PRI_MI2S_SD1",
			  "PRI_MI2S_WS",
			  "",
			  "", /* GPIO_130 */
			  "",
			  "",
			  "",
			  "",
			  "",
			  "",
			  "",
			  "",
			  "",
			  "", /* GPIO_140 */
			  "",
			  "",
			  "",
			  "",
			  "",
			  "",
			  "",
			  "",
			  "",
			  "", /* GPIO_150 */
			  "",
			  "",
			  "WLAN_SW_CTRL",
			  "",
			  "",
			  "",
			  "",
			  "",
			  "",
			  "", /* GPIO_160 */
			  "",
			  "",
			  "",
			  "",
			  "",
			  "",
			  "",
			  "",
			  "",
			  "", /* GPIO_170 */
			  "",
			  "",
			  "",
			  "",
			  "",
			  "",
			  "",
			  "",
			  "",
			  "", /* GPIO_180 */
			  "",
			  "",
			  "",
			  "",
			  "",
			  "",
			  "",
			  "",
			  "",
			  "", /* GPIO_190 */
			  "",
			  "",
			  "",
			  "",
			  "",
			  "",
			  "",
			  "",
			  "",
			  "", /* GPIO_200 */
			  "WLAN_XO_CLK",
			  "";

	/* Strap inputs with pull-ups, as downstream (nicole.dtsi:462-490) */
	pinctrl-0 = <&straps_default>;
	pinctrl-names = "default";

	/* OTG load switch enable and its over-current flag (pmic-glink) */
	usb_otg_en: usb-otg-en-state {
		pins = "gpio48";
		function = "gpio";
		drive-strength = <2>;
		bias-disable;
		output-low;
	};

	usb_ocp_n: usb-ocp-n-state {
		pins = "gpio79";
		function = "gpio";
		drive-strength = <6>;
		bias-pull-up;
	};

	straps_default: straps-default-state {
		pins = "gpio3", "gpio6", "gpio7", "gpio45", "gpio50", "gpio51";
		function = "gpio";
		drive-strength = <2>;
		bias-pull-up;
		/* no input-enable: TLMM inputs are always on (qcom,tlmm-common.yaml) */
	};

	/* nicole.dtsi:270-284 */
	sdc2_card_det_n: sd-card-det-n-state {
		pins = "gpio80";
		function = "gpio";
		drive-strength = <2>;
		bias-pull-up;
	};

	sdc2_card_det_sleep: sd-card-det-sleep-state {
		pins = "gpio80";
		function = "gpio";
		drive-strength = <2>;
		bias-disable;
	};

	/* nicole.dtsi:295-330 (gpio13 output low = AVDD on) */
	panel_avdd_en: panel-avdd-en-state {
		pins = "gpio13";
		function = "gpio";
		drive-strength = <8>;
		bias-disable;
	};

	/* pinctrl sde_dsi_active (GPIO24, 8 mA, no pull) */
	sde_dsi_active: sde-dsi-active-state {
		pins = "gpio24";
		function = "gpio";
		drive-strength = <8>;
		bias-disable;
	};

	sde_dsi_suspend: sde-dsi-suspend-state {
		pins = "gpio24";
		function = "gpio";
		drive-strength = <2>;
		bias-pull-down;
	};

	/* pinctrl:3056-3067 */
	sde_te_active: sde-te-active-state {
		pins = "gpio82";
		function = "mdp_vsync";
		drive-strength = <2>;
		bias-pull-down;
	};

	/* pinctrl:879-893 */
	qup_spi12_default: qup-spi12-default-state {
		pins = "gpio52", "gpio53", "gpio54", "gpio55";
		function = "qup12";
		drive-strength = <6>;
		bias-disable;
	};

	/* pinctrl:1609-1622 */
	ts_active: ts-active-state {
		pins = "gpio22", "gpio23";
		function = "gpio";
		drive-strength = <8>;
		bias-pull-up;
	};

	/* nicole.dtsi:449-460 */
	/* WCD938x reset (pinctrl:2839-2850) */
	wcd_reset_n: wcd-reset-n-state {
		pins = "gpio88";
		function = "gpio";
		drive-strength = <16>;
		bias-disable;
	};

	/* PRI MI2S to the speaker amps (pinctrl:2410-2510; 8 mA, no pull) */
	pri_mi2s_active: pri-mi2s-active-state {
		sck-pins {
			pins = "gpio125";
			function = "mi2s0_sck";
			drive-strength = <8>;
			bias-disable;
		};

		data0-pins {
			pins = "gpio126";
			function = "mi2s0_data0";
			drive-strength = <8>;
			bias-disable;
		};

		data1-pins {
			pins = "gpio127";
			function = "mi2s0_data1";
			drive-strength = <8>;
			bias-disable;
		};

		ws-pins {
			pins = "gpio128";
			function = "mi2s0_ws";
			drive-strength = <8>;
			bias-disable;
		};
	};

	fan_i2c_default: fan-i2c-default-state {
		pins = "gpio8", "gpio9";
		function = "gpio";
		drive-strength = <16>;
		bias-pull-up;
	};

	/* pinctrl:2880-2892 (reset) ; GPIO34 IRQ assumed, TODO(cihaz) */
	pm8008j_default: pm8008j-default-state {
		reset-n-pins {
			pins = "gpio35";
			function = "gpio";
			drive-strength = <2>;
			bias-disable;
		};

		int-pins {
			pins = "gpio34";
			function = "gpio";
			drive-strength = <2>;
			bias-disable;
		};
	};

	/* pinctrl:2895-2930 */
	pcie0_default_state: pcie0-default-state {
		perst-pins {
			pins = "gpio94";
			function = "gpio";
			drive-strength = <2>;
			bias-pull-down;
		};

		clkreq-pins {
			pins = "gpio95";
			function = "pcie0_clkreqn";
			drive-strength = <2>;
			bias-pull-up;
		};

		wake-pins {
			pins = "gpio96";
			function = "gpio";
			drive-strength = <2>;
			bias-pull-up;
		};
	};

	/* pinctrl:2-14 */
	bt_en_state: bt-en-state {
		pins = "gpio65";
		function = "gpio";
		drive-strength = <2>;
		bias-pull-down;
		output-low;
	};

	/* pinctrl:3622-3649 */
	wlan_en_state: wlan-en-state {
		pins = "gpio64";
		function = "gpio";
		drive-strength = <16>;
		bias-pull-down;
		output-low;
	};

	/* pinctrl:16-28 + nicole.dtsi:5-12 */
	wlan_xo_clk_state: wlan-xo-clk-state {
		pins = "gpio201";
		function = "gpio";
		drive-strength = <2>;
		bias-pull-down;
		output-low;
	};

	/* BT UART: QUP SE18 4-wire, GPIO68-71 (qupv3_se18_4uart,
	 * lahaina-qupv3.dtsi:843-863) */
	bt_uart_default: bt-uart-default-state {
		cts-pins {
			pins = "gpio68";
			function = "qup18";
			drive-strength = <2>;
			bias-bus-hold;
		};

		rts-pins {
			pins = "gpio69";
			function = "qup18";
			drive-strength = <2>;
			bias-disable;
		};

		tx-pins {
			pins = "gpio70";
			function = "qup18";
			drive-strength = <2>;
			bias-pull-up;
		};

		rx-pins {
			pins = "gpio71";
			function = "qup18";
			drive-strength = <2>;
			bias-pull-up;
		};
	};

	/* front camera (lahaina-pinctrl.dtsi:3249-3260, 3422-3434, 3593-3620) */
	cci1_i2c1_default: cci1-i2c1-default-state {
		pins = "gpio113", "gpio114";	/* SDA, SCL */
		function = "cci_i2c";
		drive-strength = <2>;
		bias-pull-up;
	};

	cci1_i2c1_sleep: cci1-i2c1-sleep-state {
		pins = "gpio113", "gpio114";
		function = "cci_i2c";
		drive-strength = <2>;
		bias-pull-down;
	};

	cam_mclk5_default: cam-mclk5-default-state {
		pins = "gpio105";
		function = "cam_mclk";
		drive-strength = <2>;
		bias-disable;
	};

	cam_rst5_default: cam-rst5-default-state {
		pins = "gpio115";
		function = "gpio";
		drive-strength = <2>;
		bias-disable;
	};
};

/* Debug UART (SE3), see aliases */
&uart2 {
	status = "okay";
};

/* PHASE 3: Bluetooth part of QCA6490 on QUP SE18 */
&uart18 {
	pinctrl-0 = <&bt_uart_default>;
	pinctrl-names = "default";

	status = "okay";

	bluetooth {
		compatible = "qcom,wcn6855-bt";

		vddrfacmn-supply = <&vreg_pmu_rfa_cmn_0p8>;
		vddaon-supply = <&vreg_pmu_aon_0p8>;
		vddwlcx-supply = <&vreg_pmu_wlcx_0p8>;
		vddwlmx-supply = <&vreg_pmu_wlmx_0p8>;
		vddbtcmx-supply = <&vreg_pmu_btcmx_0p8>;
		vddrfa0p8-supply = <&vreg_pmu_rfa_0p8>;
		vddrfa1p2-supply = <&vreg_pmu_rfa_1p2>;
		vddrfa1p7-supply = <&vreg_pmu_rfa_1p7>;

		max-speed = <3200000>;
	};
};

/*
 * ===================================================================
 * PROJECT CONTRACT (docs/guvenlik-kurallari.md, Seviye 4): internal UFS must stay
 * DISABLED until the Phase 3 approval. Do not enable these two nodes,
 * do not add supplies, do not "test" them. Razer's UFS config for later:
 * qrd-common:9-38 (vcc L7B 2.504-2.95 V, vccq L9B, phy L5B/L6B).
 * ===================================================================
 */
/*
 * UFS stays disabled here. Faz 3 (dar, docs/guvenlik-kurallari.md §8, 25 Ekim 2026) only allows
 * read-only access to copy the device's own firmware partitions: the extraction
 * variant flips status with fdtput (scripts/lab/ufs-oku.sh) and runs the mini
 * initramfs, which sets every sd* read-only before reading. Supplies: Razer
 * lahaina-qrd-common.dtsi:20-38 (in nicole's include chain), phy as sm8350-hdk.
 */
&ufs_mem_hc {
	reset-gpios = <&tlmm 203 GPIO_ACTIVE_LOW>;

	vcc-supply = <&pm8350_l7>;
	vcc-max-microamp = <800000>;
	vccq-supply = <&pm8350_l9>;
	vccq-max-microamp = <900000>;

	status = "disabled";
};

&ufs_mem_phy {
	vdda-phy-supply = <&pm8350_l5>;
	vdda-pll-supply = <&pm8350_l6>;

	status = "disabled";
};

/*
 * USB: only the primary controller (a600000) exists on nicole; usb1/usb_2
 * is disabled downstream (nicole.dtsi:577-587).
 * D1 (30 Ekim 2026): dual role, High-Speed only. The role switch is driven
 * from user space (device-razer-nicole: udev rule + nicole-usb-rol, which
 * copies UCSI's /sys/class/typec/port0 data_role into usb_role): with
 * pmic-glink connector@0 enabled and wired to this role switch the link
 * never came up (stuck in Suspend, the Mac saw nothing; the experiment's
 * diff is in the author's notes). Default role is
 * device, so the USB network to the Mac works with no rule at all.
 * usb_1_qmpphy is on and gives the PIPE clock; maximum-speed stays
 * high-speed until the Type-C orientation is handled (D2).
 * Host role: xHCI comes up and VBUS is sourced, but no device connects
 * yet.
 */
&usb_1 {
	/*
	 * USB 2.0 only (maximum-speed below), so take the PIPE clock from UTMI:
	 * with the Type-C graph live the QMP PHY belongs to DisplayPort, and a
	 * dwc3 fed by its pipe clock lost device mode (D2 deneme C, 31 Ekim).
	 */
	qcom,select-utmi-as-pipe-clk;

	status = "okay";
};

&usb_1_dwc3 {
	dr_mode = "otg";
	usb-role-switch;
	role-switch-default-mode = "peripheral";
	maximum-speed = "high-speed";
	phys = <&usb_1_hsphy>;
	phy-names = "usb2-phy";
};

/* lahaina-usb.dtsi:118-127: vdd L5B, vdda18 L1C, vdda33 L2B */
&usb_1_hsphy {
	vdda-pll-supply = <&pm8350_l5>;
	vdda18-supply = <&pm8350c_l1>;
	vdda33-supply = <&pm8350_l2>;

	status = "okay";
};

/* lahaina-usb.dtsi:142-150: vdd L1B, core L6B */
&usb_1_qmpphy {
	vdda-phy-supply = <&pm8350_l1>;
	vdda-pll-supply = <&pm8350_l6>;

	status = "okay";
};

&usb_1_qmpphy_out {
	remote-endpoint = <&pmic_glink_ss_in>;
};

&mdss_dp {
	status = "okay";
};

&mdss_dp_out {
	data-lanes = <0 1>;
};

/* Stage 2 of the front camera: CAMSS (Titan 580), drivers/camera/0003 + 0004 */
#include "sm8350-nicole-camss.dtsi"
